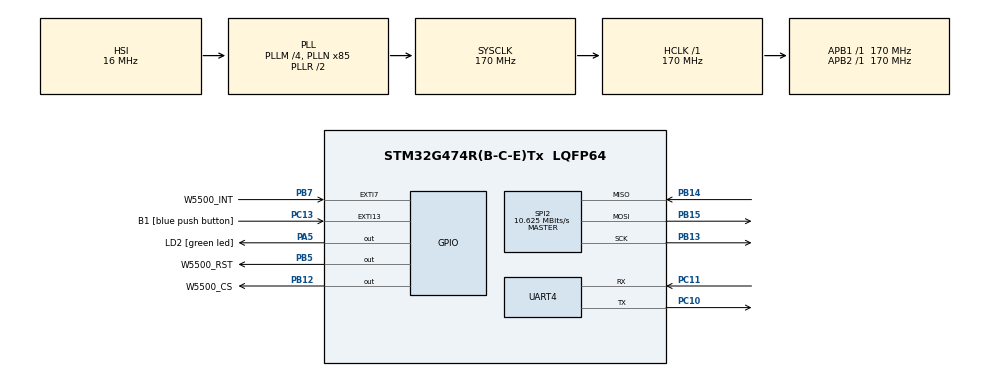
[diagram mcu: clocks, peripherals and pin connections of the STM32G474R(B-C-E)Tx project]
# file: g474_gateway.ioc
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FREERTOS.Tasks01=defaultTask,24,128,StartDefaultTask,Default,NULL,Dynamic,NULL,NULL;RS422Task,40,512,StartRS422Task,Default,NULL,Dynamic,NULL,NULL;EthernetTask,24,512,StartEthernetTask,Default,NULL,Dynamic,NULL,NULL;HealthTask,8,128,StartHealthTask,Default,NULL,Dynamic,NULL,NULL
FREERTOS.configTOTAL_HEAP_SIZE=16384
Mcu.Family=STM32G4
Mcu.Name=STM32G474R(B-C-E)Tx
Mcu.Package=LQFP64
NVIC.EXTI15_10_IRQn=true\:5\:0\:false\:false\:true\:true\:true\:true\:true
NVIC.EXTI9_5_IRQn=true\:5\:0\:false\:false\:true\:true\:true\:true\:true
NVIC.PriorityGroup=NVIC_PRIORITYGROUP_4
NVIC.TIM6_DAC_IRQn=true\:15\:0\:false\:false\:true\:false\:false\:true\:true
NVIC.TimeBase=TIM6_DAC_IRQn
NVIC.TimeBaseIP=TIM6
NVIC.UART4_IRQn=true\:5\:0\:false\:false\:true\:true\:true\:true\:true
PA13.GPIO_Label=T_SWDIO
PA13.Signal=SYS_JTMS-SWDIO
PA14.GPIO_Label=T_SWCLK
PA14.Signal=SYS_JTCK-SWCLK
PA2.GPIO_Label=LPUART1_TX [STLINKV3E_VCP_RX]
PA2.Signal=LPUART1_TX
PA3.GPIO_Label=LPUART1_RX [STLINKV3E_VCP_TX]
PA3.Signal=LPUART1_RX
PA5.GPIO_Label=LD2 [green led]
PA5.Signal=GPIO_Output
PB12.GPIO_Label=W5500_CS
PB12.GPIO_Speed=GPIO_SPEED_FREQ_HIGH
PB12.PinState=GPIO_PIN_SET
PB12.Signal=GPIO_Output
PB13.GPIO_Speed=GPIO_SPEED_FREQ_HIGH
PB13.Mode=Full_Duplex_Master
PB13.Signal=SPI2_SCK
PB14.GPIO_Speed=GPIO_SPEED_FREQ_HIGH
PB14.Mode=Full_Duplex_Master
PB14.Signal=SPI2_MISO
PB15.GPIO_Speed=GPIO_SPEED_FREQ_HIGH
PB15.Mode=Full_Duplex_Master
PB15.Signal=SPI2_MOSI
PB3.GPIO_Label=T_SWO
PB3.Signal=SYS_JTDO-SWO
PB5.GPIO_Label=W5500_RST
PB5.PinState=GPIO_PIN_SET
PB5.Signal=GPIO_Output
PB7.GPIO_Label=W5500_INT
PB7.GPIO_ModeDefaultEXTI=GPIO_MODE_IT_FALLING
PB7.Signal=GPXTI7
PC10.Mode=Asynchronous
PC10.Signal=UART4_TX
PC11.Mode=Asynchronous
PC11.Signal=UART4_RX
PC13.GPIO_Label=B1 [blue push button]
PC13.Signal=GPXTI13
PC14-OSC32_IN.GPIO_Label=RCC_OSC32_IN
PC14-OSC32_IN.Signal=RCC_OSC32_IN
PC15-OSC32_OUT.GPIO_Label=RCC_OSC32_OUT
PC15-OSC32_OUT.Signal=RCC_OSC32_OUT
PF0-OSC_IN.GPIO_Label=RCC_OSC_IN
PF0-OSC_IN.Signal=RCC_OSC_IN
PF1-OSC_OUT.GPIO_Label=RCC_OSC_OUT
PF1-OSC_OUT.Signal=RCC_OSC_OUT
ProjectManager.HeapSize=0x200
ProjectManager.StackSize=0x400
ProjectManager.TargetToolchain=STM32CubeIDE
RCC.ADC12Freq_Value=170000000
RCC.ADC345Freq_Value=170000000
RCC.AHBFreq_Value=170000000
RCC.APB1Freq_Value=170000000
RCC.APB1TimFreq_Value=170000000
RCC.APB2Freq_Value=170000000
RCC.APB2TimFreq_Value=170000000
RCC.CortexFreq_Value=170000000
RCC.EXTERNAL_CLOCK_VALUE=12288000
RCC.HCLKFreq_Value=170000000
RCC.HSE_VALUE=24000000
RCC.HSI48_VALUE=48000000
RCC.HSI_VALUE=16000000
RCC.LSE_VALUE=32768
RCC.PLLM=RCC_PLLM_DIV4
RCC.PLLN=85
RCC.RTCClockSelection=RCC_RTCCLKSOURCE_LSE
RCC.SYSCLKFreq_VALUE=170000000
RCC.SYSCLKSource=RCC_SYSCLKSOURCE_PLLCLK
RCC.USBFreq_Value=170000000
RCC.VCOOutputFreq_Value=340000000
SPI2.BaudRatePrescaler=SPI_BAUDRATEPRESCALER_16
SPI2.CalculateBaudRate=10.625 MBits/s
SPI2.DataSize=SPI_DATASIZE_8BIT
SPI2.Direction=SPI_DIRECTION_2LINES
SPI2.Mode=SPI_MODE_MASTER
SPI2.VirtualType=VM_MASTER
VP_FREERTOS_VS_CMSIS_V2.Mode=CMSIS_V2
VP_SYS_VS_DBSignals.Mode=DisableDeadBatterySignals
VP_SYS_VS_tim6.Mode=TIM6
board=NUCLEO-G474RE

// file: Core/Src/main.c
/* USER CODE BEGIN Header */
/**
  ******************************************************************************
  * @file           : main.c
  * @brief          : Main program body
  ******************************************************************************
  * @attention
  *
  * Copyright (c) 2026 STMicroelectronics.
  * All rights reserved.
  *
  * This software is licensed under terms that can be found in the LICENSE file
  * in the root directory of this software component.
  * If no LICENSE file comes with this software, it is provided AS-IS.
  *
  ******************************************************************************
  */
/* USER CODE END Header */
#include "main.h"
#include "cmsis_os.h"

/* USER CODE BEGIN Includes */
#include "FreeRTOS.h"
#include "protocol.h"
#include "stream_parser.h"

/* USER CODE END Includes */

/* USER CODE BEGIN PTD */
typedef enum
{
  RS422_PING_TEST_NOT_RUN = 0,
  RS422_PING_TEST_PASS = 1,
  RS422_PING_TEST_ENCODE_FAILURE = -1,
  RS422_PING_TEST_TX_FAILURE = -2,
  RS422_PING_TEST_PONG_TIMEOUT = -3,
  RS422_PING_TEST_RX_FAILURE = -4
} rs422_ping_test_result_t;

typedef enum
{
  COMM_INIT = 0,
  COMM_OK,
  COMM_TIMEOUT
} rs422_comm_state_t;

/* USER CODE END PTD */

/* USER CODE BEGIN PD */
#define RS422_BRINGUP_TEST_COUNT          100u
#define RS422_BRINGUP_TX_TIMEOUT_MS       100u
#define RS422_BRINGUP_PONG_TIMEOUT_MS     1000u
#define RS422_BRINGUP_INTER_TEST_DELAY_MS 20u
#define RS422_EVENT_RX                     (1UL << 0)
#define RS422_EVENT_TX_DONE                (1UL << 1)
#define RS422_EVENT_CMD_READY              (1UL << 2)
#define RS422_EVENT_TCP_CONTEXT_RESET      (1UL << 3)
#define RS422_EVENT_MASK                   (RS422_EVENT_RX | RS422_EVENT_TX_DONE | \
                                            RS422_EVENT_CMD_READY | \
                                            RS422_EVENT_TCP_CONTEXT_RESET)
#define RS422_RX_RING_CAPACITY             512u
#define RS422_RX_RING_MASK                 (RS422_RX_RING_CAPACITY - 1u)
#define RS422_CMD_QUEUE_DEPTH              8u
#define TCP_RESPONSE_QUEUE_DEPTH           8u
#define UDP_TELEMETRY_QUEUE_DEPTH          4u
#define HEALTH_TASK_PERIOD_MS              100u
#define RS422_COMM_TIMEOUT_MS              1500u
#define W5500_RESET_DELAY_MS               2u
#define W5500_SPI_TIMEOUT_MS               100u
#define W5500_VERSIONR_ADDRESS             0x0039u
#define W5500_PHYCFGR_ADDRESS              0x002eu
#define W5500_PHYCFGR_LNK                  0x01u
#define W5500_PHY_POLL_PERIOD_MS           100u
#define W5500_DATA_SERVICE_PERIOD_MS        1u
#define ETHERNET_EVENT_TCP_RESPONSE_READY  (1UL << 0)
#define ETHERNET_EVENT_MASK                ETHERNET_EVENT_TCP_RESPONSE_READY
#define DIAG_TIMESTAMP_NOT_CAPTURED_MS      UINT32_MAX
#define W5500_GAR_ADDRESS                  0x0001u
#define W5500_SUBR_ADDRESS                 0x0005u
#define W5500_SHAR_ADDRESS                 0x0009u
#define W5500_SIPR_ADDRESS                 0x000fu
#define W5500_GAR_LENGTH                   4u
#define W5500_SUBR_LENGTH                  4u
#define W5500_SHAR_LENGTH                  6u
#define W5500_SIPR_LENGTH                  4u
#define W5500_NET_MAX_REGISTER_LENGTH      W5500_SHAR_LENGTH
#define W5500_COMMON_HEADER_LENGTH         3u
/* BSB[4:0] = 00000 (Common), RWB = 0 (Read), OM[1:0] = 00 (VDM). */
#define W5500_COMMON_READ_VDM              0x00u
/* BSB[4:0] = 00000 (Common), RWB = 1 (Write), OM[1:0] = 00 (VDM). */
#define W5500_COMMON_WRITE_VDM             0x04u
#define W5500_SOCKET0_READ_VDM             0x08u
#define W5500_SOCKET0_WRITE_VDM            0x0cu
#define W5500_SOCKET0_MR_ADDRESS           0x0000u
#define W5500_SOCKET0_CR_ADDRESS           0x0001u
#define W5500_SOCKET0_IR_ADDRESS           0x0002u
#define W5500_SOCKET0_SR_ADDRESS           0x0003u
#define W5500_SOCKET0_PORT_ADDRESS         0x0004u
#define W5500_SOCKET0_TX_FSR_ADDRESS       0x0020u
#define W5500_SOCKET0_TX_WR_ADDRESS        0x0024u
#define W5500_SOCKET0_RX_RSR_ADDRESS       0x0026u
#define W5500_SOCKET0_RX_RD_ADDRESS        0x0028u
#define W5500_SOCKET0_MAX_DATA_LENGTH      2u
#define W5500_SOCKET0_TX_BUFFER_WRITE_VDM  0x14u
#define W5500_SOCKET0_RX_BUFFER_READ_VDM   0x18u
#define W5500_SOCKET0_TCP_MODE             0x01u
#define W5500_SOCKET0_OPEN_COMMAND         0x01u
#define W5500_SOCKET0_LISTEN_COMMAND       0x02u
#define W5500_SOCKET0_DISCON_COMMAND       0x08u
#define W5500_SOCKET0_CLOSE_COMMAND        0x10u
#define W5500_SOCKET0_SEND_COMMAND         0x20u
#define W5500_SOCKET0_RECV_COMMAND         0x40u
#define W5500_SOCKET0_IR_SEND_OK           0x10u
#define W5500_SOCKET0_IR_TIMEOUT           0x08u
#define W5500_SOCKET0_STATUS_CLOSED        0x00u
#define W5500_SOCKET0_STATUS_INIT          0x13u
#define W5500_SOCKET0_STATUS_LISTEN        0x14u
#define W5500_SOCKET0_STATUS_SYNSENT       0x15u
#define W5500_SOCKET0_STATUS_SYNRECV       0x16u
#define W5500_SOCKET0_STATUS_ESTABLISHED   0x17u
#define W5500_SOCKET0_STATUS_FIN_WAIT      0x18u
#define W5500_SOCKET0_STATUS_CLOSING       0x1au
#define W5500_SOCKET0_STATUS_TIME_WAIT     0x1bu
#define W5500_SOCKET0_STATUS_CLOSE_WAIT    0x1cu
#define W5500_SOCKET0_STATUS_LAST_ACK      0x1du
#define W5500_TCP_SERVER_PORT              5000u
#define W5500_SOCKET_STATE_TIMEOUT_MS      1000u
#define W5500_SOCKET_STATE_POLL_MS         10u
#define W5500_TCP_TRANSIENT_TIMEOUT_MS     3000u
#define W5500_TCP_RECOVERY_RETRY_MS        500u
#define W5500_TCP_STABLE_READ_ATTEMPTS     8u
#define W5500_TCP_RX_CHUNK_SIZE            64u
#define W5500_TCP_TX_FREE_TIMEOUT_MS       1000u
#define W5500_TCP_SEND_TIMEOUT_MS          1000u
#define W5500_TCP_IO_POLL_MS               10u
#define W5500_SOCKET_COMMAND_TIMEOUT_MS    100u
#define W5500_SOCKET_COMMAND_POLL_MS       1u
#define W5500_SOCKET1_READ_VDM             0x28u
#define W5500_SOCKET1_WRITE_VDM            0x2cu
#define W5500_SOCKET1_TX_BUFFER_WRITE_VDM  0x34u
#define W5500_SOCKET1_MR_ADDRESS           0x0000u
#define W5500_SOCKET1_CR_ADDRESS           0x0001u
#define W5500_SOCKET1_IR_ADDRESS           0x0002u
#define W5500_SOCKET1_SR_ADDRESS           0x0003u
#define W5500_SOCKET1_PORT_ADDRESS         0x0004u
#define W5500_SOCKET1_DIPR_ADDRESS         0x000cu
#define W5500_SOCKET1_DPORT_ADDRESS        0x0010u
#define W5500_SOCKET1_TX_FSR_ADDRESS       0x0020u
#define W5500_SOCKET1_TX_WR_ADDRESS        0x0024u
#define W5500_SOCKET1_MAX_DATA_LENGTH      4u
#define W5500_SOCKET1_UDP_MODE             0x02u
#define W5500_SOCKET1_OPEN_COMMAND         0x01u
#define W5500_SOCKET1_SEND_COMMAND         0x20u
#define W5500_SOCKET1_IR_SEND_OK           0x10u
#define W5500_SOCKET1_IR_TIMEOUT           0x08u
#define W5500_SOCKET1_STATUS_CLOSED        0x00u
#define W5500_SOCKET1_STATUS_UDP           0x22u
#define W5500_UDP_LOCAL_PORT               5001u
#define W5500_UDP_DESTINATION_PORT         5002u
#define W5500_UDP_PAYLOAD_LENGTH           6u
#define W5500_UDP_STABLE_READ_ATTEMPTS     8u
#define W5500_UDP_TX_FREE_TIMEOUT_MS       1000u
#define W5500_UDP_SEND_TIMEOUT_MS          1000u
#define W5500_UDP_IO_POLL_MS               10u
#define W5500_UDP_SPI_CHUNK_SIZE           64u
/* Day 8 forwards only F429 telemetry; retain the Day 6 generator disabled. */
#define W5500_UDP_LOCAL_TELEMETRY_ENABLED  0u
/* F429 produces every 100 ms; two sends clear one-cycle scheduling backlog. */
#define UDP_TELEMETRY_DRAIN_LIMIT          2u

/* USER CODE END PD */

SPI_HandleTypeDef hspi2;

UART_HandleTypeDef huart4;

/* Definitions for defaultTask */
osThreadId_t defaultTaskHandle;
const osThreadAttr_t defaultTask_attributes = {
  .name = "defaultTask",
  .priority = (osPriority_t) osPriorityNormal,
  .stack_size = 128 * 4
};
/* Definitions for RS422Task */
osThreadId_t RS422TaskHandle;
const osThreadAttr_t RS422Task_attributes = {
  .name = "RS422Task",
  .priority = (osPriority_t) osPriorityHigh,
  .stack_size = 512 * 4
};
/* Definitions for EthernetTask */
osThreadId_t EthernetTaskHandle;
const osThreadAttr_t EthernetTask_attributes = {
  .name = "EthernetTask",
  .priority = (osPriority_t) osPriorityNormal,
  .stack_size = 512 * 4
};
/* Definitions for HealthTask */
osThreadId_t HealthTaskHandle;
const osThreadAttr_t HealthTask_attributes = {
  .name = "HealthTask",
  .priority = (osPriority_t) osPriorityLow,
  .stack_size = 128 * 4
};
/* USER CODE BEGIN PV */
static volatile int32_t g_rs422_ping_test_result = RS422_PING_TEST_NOT_RUN;
static volatile uint8_t g_rs422_last_msg_id = 0u;
static volatile uint16_t g_rs422_last_seq = 0u;
static volatile uint32_t g_rs422_rx_frame_count = 0u;
static volatile uint32_t g_rs422_test_total = 0u;
static volatile uint32_t g_rs422_test_success = 0u;
static volatile uint32_t g_rs422_test_fail = 0u;
static volatile uint32_t g_rs422_rx_overflow_count = 0u;
static volatile uint32_t g_rs422_uart_rx_error_count = 0u;
static volatile uint32_t g_rs422_tx_busy = 0u;
static volatile uint32_t g_rs422_tx_complete_count = 0u;
static volatile uint32_t g_rs422_tx_busy_count = 0u;
static volatile uint32_t g_rs422_tx_error_count = 0u;
static volatile uint32_t g_rs422_tx_timeout_count = 0u;
static volatile uint32_t g_rs422_cmd_enqueue_success_count = 0u;
static volatile uint32_t g_rs422_cmd_enqueue_fail_count = 0u;
static volatile uint32_t g_rs422_cmd_dequeue_count = 0u;
static volatile uint32_t g_rs422_forwarded_pong_rx_count = 0u;
static volatile uint32_t g_tcp_response_enqueue_success_count = 0u;
static volatile uint32_t g_tcp_response_enqueue_fail_count = 0u;
static volatile uint32_t g_tcp_response_dequeue_count = 0u;
static volatile uint32_t g_rs422_telemetry_rx_count = 0u;
static volatile uint32_t g_udp_telemetry_enqueue_success_count = 0u;
static volatile uint32_t g_udp_telemetry_enqueue_fail_count = 0u;
static volatile uint32_t g_udp_telemetry_dequeue_count = 0u;
static volatile uint32_t g_rs422_telemetry_forwarding_enabled = 0u;
static volatile uint32_t g_rs422_tcp_ping_pending = 0u;
static volatile uint16_t g_rs422_tcp_ping_pending_seq = 0u;
static volatile uint8_t g_rs422_last_tx_msg_id = 0u;
static volatile uint16_t g_rs422_last_tx_seq = 0u;
static volatile uint32_t g_rs422_last_valid_frame_tick = 0u;
static volatile uint32_t g_rs422_has_valid_frame = 0u;
static volatile rs422_comm_state_t g_rs422_comm_state = COMM_INIT;
static volatile uint32_t g_rs422_comm_timeout_count = 0u;
static volatile uint32_t g_rs422_comm_recovery_count = 0u;
static volatile uint32_t g_rs422_diag_last_valid_frame_ms =
  DIAG_TIMESTAMP_NOT_CAPTURED_MS;
static volatile uint32_t g_rs422_diag_timeout_transition_ms =
  DIAG_TIMESTAMP_NOT_CAPTURED_MS;
static volatile uint32_t g_rs422_diag_recovery_first_valid_ms =
  DIAG_TIMESTAMP_NOT_CAPTURED_MS;
static volatile uint32_t g_rs422_diag_recovery_comm_ok_ms =
  DIAG_TIMESTAMP_NOT_CAPTURED_MS;
static volatile uint32_t g_rs422_diag_fault_detection_ms =
  DIAG_TIMESTAMP_NOT_CAPTURED_MS;
static volatile uint32_t g_rs422_diag_recovery_ms =
  DIAG_TIMESTAMP_NOT_CAPTURED_MS;
static volatile uint32_t g_rs422_diag_timeout_transition_tick = UINT32_MAX;
static volatile uint32_t g_rs422_diag_recovery_first_valid_tick = UINT32_MAX;
static volatile uint32_t g_rs422_diag_recovery_comm_ok_tick = UINT32_MAX;
static volatile uint32_t g_gateway_queue_init_ok = 0u;
static volatile uint32_t g_gateway_free_heap_bytes = 0u;
static volatile uint32_t g_gateway_min_ever_free_heap_bytes = 0u;
static volatile uint8_t g_w5500_version = 0u;
/* -1: not completed; otherwise HAL_OK/ERROR/BUSY/TIMEOUT = 0/1/2/3. */
static volatile int32_t g_w5500_spi_status = -1;
/* Retain the last successful PHY sample on error; always check PHY SPI status. */
static volatile uint8_t g_w5500_phycfgr = 0u;
static volatile uint32_t g_w5500_link_up = 0u;
static volatile uint32_t g_w5500_link_down_count = 0u;
static volatile uint32_t g_w5500_link_recovery_count = 0u;
static volatile int32_t g_w5500_phy_spi_status = -1;
static volatile uint32_t g_w5500_net_config_ok = 0u;
static volatile uint32_t g_w5500_net_readback_ok = 0u;
static volatile int32_t g_w5500_net_write_status = -1;
static volatile int32_t g_w5500_net_read_status = -1;
static uint8_t g_w5500_gar_readback[W5500_GAR_LENGTH] = {0u};
static uint8_t g_w5500_subr_readback[W5500_SUBR_LENGTH] = {0u};
static uint8_t g_w5500_shar_readback[W5500_SHAR_LENGTH] = {0u};
static uint8_t g_w5500_sipr_readback[W5500_SIPR_LENGTH] = {0u};
static const uint8_t g_w5500_net_gateway[W5500_GAR_LENGTH] = {
  0u, 0u, 0u, 0u
};
static const uint8_t g_w5500_net_subnet[W5500_SUBR_LENGTH] = {
  255u, 255u, 255u, 0u
};
static const uint8_t g_w5500_net_mac[W5500_SHAR_LENGTH] = {
  0x02u, 0x00u, 0x00u, 0x00u, 0x00u, 0x02u
};
static const uint8_t g_w5500_net_ip[W5500_SIPR_LENGTH] = {
  192u, 168u, 77u, 2u
};
static volatile uint32_t g_w5500_tcp_init_ok = 0u;
static volatile uint32_t g_w5500_tcp_listen_ok = 0u;
static volatile uint8_t g_w5500_socket0_status = W5500_SOCKET0_STATUS_CLOSED;
static volatile int32_t g_w5500_socket0_spi_status = -1;
static volatile uint32_t g_w5500_tcp_rx_bytes = 0u;
static volatile uint32_t g_w5500_tcp_tx_bytes = 0u;
static volatile uint32_t g_w5500_tcp_valid_frame_count = 0u;
static volatile uint32_t g_w5500_tcp_ping_count = 0u;
static volatile uint32_t g_w5500_tcp_pong_count = 0u;
static volatile uint8_t g_w5500_tcp_last_rx_msg_id = 0u;
static volatile uint16_t g_w5500_tcp_last_rx_seq = 0u;
static volatile uint8_t g_w5500_tcp_last_tx_msg_id = 0u;
static volatile uint16_t g_w5500_tcp_last_tx_seq = 0u;
static volatile uint32_t g_w5500_tcp_rx_error_count = 0u;
static volatile uint32_t g_w5500_tcp_tx_error_count = 0u;
static volatile int32_t g_w5500_tcp_last_rx_status = -1;
static volatile int32_t g_w5500_tcp_last_tx_status = -1;
static volatile uint32_t g_w5500_tcp_recovery_pending = 0u;
static volatile uint32_t g_w5500_tcp_recovery_attempt_count = 0u;
static volatile uint32_t g_w5500_tcp_recovery_success_count = 0u;
static volatile uint32_t g_w5500_tcp_recovery_fail_count = 0u;
static volatile uint32_t g_eth_diag_link_down_observed_ms =
  DIAG_TIMESTAMP_NOT_CAPTURED_MS;
static volatile uint32_t g_eth_diag_link_up_observed_ms =
  DIAG_TIMESTAMP_NOT_CAPTURED_MS;
static volatile uint32_t g_eth_diag_tcp_service_ready_ms =
  DIAG_TIMESTAMP_NOT_CAPTURED_MS;
static volatile uint32_t g_eth_diag_first_tcp_pong_tx_success_ms =
  DIAG_TIMESTAMP_NOT_CAPTURED_MS;
static volatile uint32_t g_eth_diag_first_udp_tx_success_ms =
  DIAG_TIMESTAMP_NOT_CAPTURED_MS;
static volatile uint32_t g_eth_diag_linkup_to_tcp_service_ready_ms =
  DIAG_TIMESTAMP_NOT_CAPTURED_MS;
static volatile uint32_t g_eth_diag_linkup_to_tcp_pong_tx_ms =
  DIAG_TIMESTAMP_NOT_CAPTURED_MS;
static volatile uint32_t g_eth_diag_linkup_to_udp_tx_ms =
  DIAG_TIMESTAMP_NOT_CAPTURED_MS;
static volatile uint32_t g_eth_diag_recovery_cycle_active = 0u;
static volatile uint32_t g_eth_diag_link_down_tick = UINT32_MAX;
static volatile uint32_t g_eth_diag_link_up_tick = UINT32_MAX;
static volatile uint32_t g_eth_diag_tcp_service_ready_tick = UINT32_MAX;
static volatile uint32_t g_eth_diag_first_tcp_pong_tx_success_tick =
  UINT32_MAX;
static volatile uint32_t g_eth_diag_first_udp_tx_success_tick = UINT32_MAX;
static volatile uint32_t g_w5500_tcp_session_active = 0u;
static volatile uint32_t g_w5500_tcp_stale_response_drop_count = 0u;
static volatile uint32_t g_w5500_data_service_cycle_count = 0u;
static volatile uint32_t g_w5500_data_deadline_miss_count = 0u;
static volatile uint32_t g_w5500_data_overrun_count = 0u;
static volatile uint32_t g_w5500_data_max_start_late_ticks = 0u;
static volatile uint32_t g_w5500_data_max_exec_cycles = 0u;
static volatile uint32_t g_w5500_data_max_exec_us = 0u;
static volatile uint32_t g_w5500_data_cycle_counter_available = 0u;
static volatile uint32_t g_w5500_data_system_core_clock_hz = 0u;
static volatile uint32_t g_w5500_data_kernel_tick_hz = 0u;
static volatile uint32_t g_w5500_data_period_cycles = 0u;
static volatile uint32_t g_w5500_data_timing_reference_valid = 0u;
static volatile uint32_t g_diag_tcp_established_ms =
  DIAG_TIMESTAMP_NOT_CAPTURED_MS;
static volatile uint32_t g_diag_first_rx_ready_ms =
  DIAG_TIMESTAMP_NOT_CAPTURED_MS;
static volatile uint32_t g_diag_first_ping_parsed_ms =
  DIAG_TIMESTAMP_NOT_CAPTURED_MS;
static volatile uint32_t g_diag_rs422_ping_tx_ms =
  DIAG_TIMESTAMP_NOT_CAPTURED_MS;
static volatile uint32_t g_diag_matching_pong_rx_ms =
  DIAG_TIMESTAMP_NOT_CAPTURED_MS;
static volatile uint32_t g_diag_tcp_pong_send_ms =
  DIAG_TIMESTAMP_NOT_CAPTURED_MS;
static volatile uint32_t g_diag_established_to_rx_ready_ms =
  DIAG_TIMESTAMP_NOT_CAPTURED_MS;
static volatile uint32_t g_diag_rx_ready_to_ping_parsed_ms =
  DIAG_TIMESTAMP_NOT_CAPTURED_MS;
static volatile uint32_t g_diag_ping_parsed_to_rs422_tx_ms =
  DIAG_TIMESTAMP_NOT_CAPTURED_MS;
static volatile uint32_t g_diag_rs422_tx_to_matching_pong_rx_ms =
  DIAG_TIMESTAMP_NOT_CAPTURED_MS;
static volatile uint32_t g_diag_matching_pong_rx_to_tcp_send_ms =
  DIAG_TIMESTAMP_NOT_CAPTURED_MS;
static volatile uint32_t g_diag_established_to_tcp_pong_send_ms =
  DIAG_TIMESTAMP_NOT_CAPTURED_MS;
static volatile uint16_t g_diag_first_ping_seq = 0u;
static volatile uint32_t g_diag_first_ping_seq_valid = 0u;
static volatile uint32_t g_w5500_udp_open_ok = 0u;
static volatile uint8_t g_w5500_udp_socket1_status = W5500_SOCKET1_STATUS_CLOSED;
static volatile int32_t g_w5500_udp_socket1_spi_status = -1;
static volatile uint32_t g_w5500_udp_tx_packet_count = 0u;
static volatile uint32_t g_w5500_udp_tx_bytes = 0u;
static volatile uint32_t g_w5500_udp_tx_error_count = 0u;
static volatile uint16_t g_w5500_udp_last_tx_seq = 0u;
static volatile int32_t g_w5500_udp_last_tx_status = -1;
static volatile uint16_t g_w5500_udp_next_seq = 1u;
static osMessageQueueId_t rs422_cmd_queue = NULL;
static osMessageQueueId_t tcp_response_queue = NULL;
static osMessageQueueId_t udp_telemetry_queue = NULL;
static const osMessageQueueAttr_t rs422_cmd_queue_attributes = {
  .name = "rs422_cmd_queue"
};
static const osMessageQueueAttr_t tcp_response_queue_attributes = {
  .name = "tcp_response_queue"
};
static const osMessageQueueAttr_t udp_telemetry_queue_attributes = {
  .name = "udp_telemetry_queue"
};
static protocol_packet_t g_rs422_ping_packet;
static protocol_packet_t g_rs422_command_packet;
static protocol_packet_t g_rs422_received_packet;
static stream_parser_t g_rs422_parser;
static uint8_t g_rs422_tx_frame[PROTOCOL_MAX_FRAME_SIZE];
static uint8_t g_uart4_rx_byte;
static uint8_t g_rs422_rx_ring[RS422_RX_RING_CAPACITY];
static volatile uint16_t g_rs422_rx_head = 0u;
static volatile uint16_t g_rs422_rx_tail = 0u;
static stream_parser_t g_tcp_parser;
static protocol_packet_t g_tcp_received_packet;
static protocol_packet_t g_tcp_pong_packet;
static uint8_t g_w5500_tcp_rx_chunk[W5500_TCP_RX_CHUNK_SIZE];
static uint8_t g_w5500_tcp_rx_dummy[W5500_TCP_RX_CHUNK_SIZE];
static uint8_t g_w5500_tcp_tx_frame[PROTOCOL_MAX_FRAME_SIZE];
static const uint8_t g_w5500_udp_destination_ip[4] = {
  192u, 168u, 77u, 1u
};
static protocol_packet_t g_udp_telemetry_packet;
static protocol_packet_t g_udp_forward_packet;
static uint8_t g_w5500_udp_tx_frame[PROTOCOL_MAX_FRAME_SIZE];
static uint8_t g_w5500_udp_spi_discard[W5500_UDP_SPI_CHUNK_SIZE];

/* USER CODE END PV */

void SystemClock_Config(void);
static void MX_GPIO_Init(void);
static void MX_SPI2_Init(void);
static void MX_UART4_Init(void);
void StartDefaultTask(void *argument);
void StartRS422Task(void *argument);
void StartEthernetTask(void *argument);
void StartHealthTask(void *argument);

/* USER CODE BEGIN PFP */
static void rs422_rx_ring_push_from_isr(uint8_t byte);
static uint32_t rs422_rx_ring_pop(uint8_t *byte);
static uint32_t rs422_ms_to_kernel_ticks(uint32_t time_ms);
static uint32_t rs422_kernel_ticks_to_ms(uint32_t ticks);
static void rs422_diag_record_timeout_transition(
  uint32_t timeout_tick,
  uint32_t has_valid_frame,
  uint32_t last_valid_frame_tick);
static void ethernet_diag_initialize(void);
static void ethernet_diag_arm_recovery(uint32_t link_down_tick);
static void ethernet_diag_record_link_up(uint32_t link_up_tick);
static void ethernet_diag_record_tcp_service_ready(void);
static void ethernet_diag_record_tcp_pong_tx_success(void);
static void ethernet_diag_record_udp_tx_success(void);
static uint32_t diagnostic_now_ms(void);
static void diagnostic_begin_tcp_session(uint32_t established_ms);
static uint32_t rs422_process_rx_buffer(
  uint16_t expected_pong_sequence,
  uint32_t match_pong);
static void rs422_handle_tcp_context_reset_event(uint32_t flags);
static void rs422_handle_tx_done_event(uint32_t flags);
static int32_t rs422_wait_for_tx_complete(
  uint16_t expected_pong_sequence,
  uint32_t *matching_pong_received);
static int32_t rs422_ping_bringup_test(uint16_t sequence);
static int32_t rs422_ping_bringup_run(void);
static int32_t rs422_forward_packet(const protocol_packet_t *packet);
static void w5500_hardware_reset(void);
static HAL_StatusTypeDef w5500_read_version(uint8_t *version);
static HAL_StatusTypeDef w5500_read_common_register(uint16_t address, uint8_t *value);
static HAL_StatusTypeDef w5500_write_common_registers(
  uint16_t address,
  const uint8_t *data,
  uint16_t length);
static HAL_StatusTypeDef w5500_read_common_registers(
  uint16_t address,
  uint8_t *data,
  uint16_t length);
static HAL_StatusTypeDef w5500_write_network_config(void);
static HAL_StatusTypeDef w5500_read_network_config(void);
static uint32_t w5500_network_readback_matches(void);
static HAL_StatusTypeDef w5500_socket0_write_registers(
  uint16_t address,
  const uint8_t *data,
  uint16_t length);
static HAL_StatusTypeDef w5500_socket0_read_register(
  uint16_t address,
  uint8_t *value);
static HAL_StatusTypeDef w5500_socket0_execute_command(uint8_t command);
static HAL_StatusTypeDef w5500_socket0_read_registers(
  uint16_t address,
  uint8_t *data,
  uint16_t length);
static HAL_StatusTypeDef w5500_socket0_read_u16(
  uint16_t address,
  uint16_t *value);
static HAL_StatusTypeDef w5500_socket0_read_stable_u16(
  uint16_t address,
  uint16_t *value);
static HAL_StatusTypeDef w5500_socket0_write_tx_buffer(
  uint16_t address,
  const uint8_t *data,
  uint16_t length);
static HAL_StatusTypeDef w5500_socket0_read_rx_buffer(
  uint16_t address,
  uint8_t *data,
  uint16_t length);
static HAL_StatusTypeDef w5500_tcp_wait_for_tx_free(
  uint16_t required_size);
static HAL_StatusTypeDef w5500_tcp_wait_for_send_result(void);
static HAL_StatusTypeDef w5500_tcp_send_frame(
  const uint8_t *frame,
  uint16_t frame_length);
static void w5500_tcp_send_response_packet(const protocol_packet_t *packet);
static void w5500_tcp_handle_valid_frame(void);
static HAL_StatusTypeDef w5500_tcp_process_rx(void);
static HAL_StatusTypeDef w5500_wait_for_socket0_status(
  uint8_t expected_status,
  uint32_t timeout_ms);
static HAL_StatusTypeDef w5500_listen_tcp_server(void);
static HAL_StatusTypeDef w5500_start_tcp_server(void);
static HAL_StatusTypeDef w5500_restart_tcp_server(void);
static uint32_t w5500_tcp_is_transient_state(uint8_t socket_status);
static void w5500_tcp_invalidate_connection_context(void);
static void w5500_tcp_discard_stale_responses(void);
static void w5500_tcp_drain_response_queue(void);
static HAL_StatusTypeDef w5500_socket1_write_registers(
  uint16_t address,
  const uint8_t *data,
  uint16_t length);
static HAL_StatusTypeDef w5500_socket1_read_register(
  uint16_t address,
  uint8_t *value);
static HAL_StatusTypeDef w5500_socket1_read_registers(
  uint16_t address,
  uint8_t *data,
  uint16_t length);
static HAL_StatusTypeDef w5500_socket1_read_u16(
  uint16_t address,
  uint16_t *value);
static HAL_StatusTypeDef w5500_socket1_read_stable_u16(
  uint16_t address,
  uint16_t *value);
static HAL_StatusTypeDef w5500_socket1_write_tx_buffer(
  uint16_t address,
  const uint8_t *data,
  uint16_t length);
static HAL_StatusTypeDef w5500_socket1_execute_command(uint8_t command);
static HAL_StatusTypeDef w5500_wait_for_socket1_status(
  uint8_t expected_status,
  uint32_t timeout_ms);
static HAL_StatusTypeDef w5500_udp_wait_for_tx_free(
  uint16_t required_size);
static HAL_StatusTypeDef w5500_udp_wait_for_send_result(void);
static HAL_StatusTypeDef w5500_udp_send_frame(
  const uint8_t *frame,
  uint16_t frame_length);
static HAL_StatusTypeDef w5500_start_udp_socket(void);
static uint32_t w5500_kernel_uptime_ms(void);
static void w5500_udp_send_telemetry(void);
static HAL_StatusTypeDef w5500_udp_forward_packet(
  const protocol_packet_t *packet);

/* USER CODE END PFP */

/* USER CODE BEGIN 0 */
static void w5500_hardware_reset(void)
{
  /* Add one tick so tick phase cannot shorten either delay below 2 ms.
     Reset low must be >= 500 us; PLL lock takes at most 1 ms after release. */
  const uint32_t delay_ticks = (uint32_t)(
    (((uint64_t)W5500_RESET_DELAY_MS * osKernelGetTickFreq()) + 999u) / 1000u) + 1u;

  HAL_GPIO_WritePin(W5500_CS_GPIO_Port, W5500_CS_Pin, GPIO_PIN_SET);
  HAL_GPIO_WritePin(W5500_RST_GPIO_Port, W5500_RST_Pin, GPIO_PIN_RESET);
  (void)osDelay(delay_ticks);
  HAL_GPIO_WritePin(W5500_RST_GPIO_Port, W5500_RST_Pin, GPIO_PIN_SET);
  (void)osDelay(delay_ticks);
}

static HAL_StatusTypeDef w5500_read_version(uint8_t *version)
{
  return w5500_read_common_register(W5500_VERSIONR_ADDRESS, version);
}

static HAL_StatusTypeDef w5500_read_common_register(uint16_t address, uint8_t *value)
{
  const uint8_t tx[4] = {
    (uint8_t)(address >> 8),
    (uint8_t)(address & 0xffu),
    W5500_COMMON_READ_VDM,
    0u /* Dummy byte clocks the register data out on MISO. */
  };
  uint8_t rx[4] = {0u};

  /* Keep CS low for address, control and data in one full-duplex transfer. */
  HAL_GPIO_WritePin(W5500_CS_GPIO_Port, W5500_CS_Pin, GPIO_PIN_RESET);
  const HAL_StatusTypeDef status = HAL_SPI_TransmitReceive(
    &hspi2, tx, rx, (uint16_t)sizeof(tx), W5500_SPI_TIMEOUT_MS);
  HAL_GPIO_WritePin(W5500_CS_GPIO_Port, W5500_CS_Pin, GPIO_PIN_SET);

  if (status == HAL_OK)
  {
    *value = rx[3];
  }

  return status;
}

static HAL_StatusTypeDef w5500_write_common_registers(
  uint16_t address,
  const uint8_t *data,
  uint16_t length)
{
  uint8_t tx[W5500_COMMON_HEADER_LENGTH + W5500_NET_MAX_REGISTER_LENGTH];

  /* length is the Data Phase byte count; it excludes address and control. */
  if ((data == NULL) || (length == 0u) ||
      (length > W5500_NET_MAX_REGISTER_LENGTH))
  {
    return HAL_ERROR;
  }

  tx[0] = (uint8_t)(address >> 8);
  tx[1] = (uint8_t)(address & 0xffu);
  tx[2] = W5500_COMMON_WRITE_VDM;
  for (uint16_t index = 0u; index < length; index++)
  {
    tx[W5500_COMMON_HEADER_LENGTH + index] = data[index];
  }

  HAL_GPIO_WritePin(W5500_CS_GPIO_Port, W5500_CS_Pin, GPIO_PIN_RESET);
  const HAL_StatusTypeDef status = HAL_SPI_Transmit(
    &hspi2,
    tx,
    (uint16_t)(W5500_COMMON_HEADER_LENGTH + length),
    W5500_SPI_TIMEOUT_MS);
  HAL_GPIO_WritePin(W5500_CS_GPIO_Port, W5500_CS_Pin, GPIO_PIN_SET);

  return status;
}

static HAL_StatusTypeDef w5500_read_common_registers(
  uint16_t address,
  uint8_t *data,
  uint16_t length)
{
  uint8_t tx[W5500_COMMON_HEADER_LENGTH + W5500_NET_MAX_REGISTER_LENGTH] = {0u};
  uint8_t rx[W5500_COMMON_HEADER_LENGTH + W5500_NET_MAX_REGISTER_LENGTH] = {0u};

  /* length is the Data Phase byte count; it excludes address and control. */
  if ((data == NULL) || (length == 0u) ||
      (length > W5500_NET_MAX_REGISTER_LENGTH))
  {
    return HAL_ERROR;
  }

  tx[0] = (uint8_t)(address >> 8);
  tx[1] = (uint8_t)(address & 0xffu);
  tx[2] = W5500_COMMON_READ_VDM;

  HAL_GPIO_WritePin(W5500_CS_GPIO_Port, W5500_CS_Pin, GPIO_PIN_RESET);
  const HAL_StatusTypeDef status = HAL_SPI_TransmitReceive(
    &hspi2,
    tx,
    rx,
    (uint16_t)(W5500_COMMON_HEADER_LENGTH + length),
    W5500_SPI_TIMEOUT_MS);
  HAL_GPIO_WritePin(W5500_CS_GPIO_Port, W5500_CS_Pin, GPIO_PIN_SET);

  if (status == HAL_OK)
  {
    for (uint16_t index = 0u; index < length; index++)
    {
      data[index] = rx[W5500_COMMON_HEADER_LENGTH + index];
    }
  }

  return status;
}

static HAL_StatusTypeDef w5500_write_network_config(void)
{
  HAL_StatusTypeDef status = w5500_write_common_registers(
    W5500_GAR_ADDRESS, g_w5500_net_gateway, W5500_GAR_LENGTH);

  if (status == HAL_OK)
  {
    status = w5500_write_common_registers(
      W5500_SUBR_ADDRESS, g_w5500_net_subnet, W5500_SUBR_LENGTH);
  }
  if (status == HAL_OK)
  {
    status = w5500_write_common_registers(
      W5500_SHAR_ADDRESS, g_w5500_net_mac, W5500_SHAR_LENGTH);
  }
  if (status == HAL_OK)
  {
    status = w5500_write_common_registers(
      W5500_SIPR_ADDRESS, g_w5500_net_ip, W5500_SIPR_LENGTH);
  }

  return status;
}

static HAL_StatusTypeDef w5500_read_network_config(void)
{
  HAL_StatusTypeDef status = w5500_read_common_registers(
    W5500_GAR_ADDRESS, g_w5500_gar_readback, W5500_GAR_LENGTH);

  if (status == HAL_OK)
  {
    status = w5500_read_common_registers(
      W5500_SUBR_ADDRESS, g_w5500_subr_readback, W5500_SUBR_LENGTH);
  }
  if (status == HAL_OK)
  {
    status = w5500_read_common_registers(
      W5500_SHAR_ADDRESS, g_w5500_shar_readback, W5500_SHAR_LENGTH);
  }
  if (status == HAL_OK)
  {
    status = w5500_read_common_registers(
      W5500_SIPR_ADDRESS, g_w5500_sipr_readback, W5500_SIPR_LENGTH);
  }

  return status;
}

static uint32_t w5500_network_readback_matches(void)
{
  for (uint16_t index = 0u; index < W5500_GAR_LENGTH; index++)
  {
    if ((g_w5500_gar_readback[index] != g_w5500_net_gateway[index]) ||
        (g_w5500_subr_readback[index] != g_w5500_net_subnet[index]) ||
        (g_w5500_sipr_readback[index] != g_w5500_net_ip[index]))
    {
      return 0u;
    }
  }

  for (uint16_t index = 0u; index < W5500_SHAR_LENGTH; index++)
  {
    if (g_w5500_shar_readback[index] != g_w5500_net_mac[index])
    {
      return 0u;
    }
  }

  return 1u;
}

static HAL_StatusTypeDef w5500_socket0_write_registers(
  uint16_t address,
  const uint8_t *data,
  uint16_t length)
{
  uint8_t tx[W5500_COMMON_HEADER_LENGTH + W5500_SOCKET0_MAX_DATA_LENGTH];

  if ((data == NULL) || (length == 0u) ||
      (length > W5500_SOCKET0_MAX_DATA_LENGTH))
  {
    return HAL_ERROR;
  }

  tx[0] = (uint8_t)(address >> 8);
  tx[1] = (uint8_t)(address & 0xffu);
  tx[2] = W5500_SOCKET0_WRITE_VDM;
  for (uint16_t index = 0u; index < length; index++)
  {
    tx[W5500_COMMON_HEADER_LENGTH + index] = data[index];
  }

  HAL_GPIO_WritePin(W5500_CS_GPIO_Port, W5500_CS_Pin, GPIO_PIN_RESET);
  const HAL_StatusTypeDef status = HAL_SPI_Transmit(
    &hspi2,
    tx,
    (uint16_t)(W5500_COMMON_HEADER_LENGTH + length),
    W5500_SPI_TIMEOUT_MS);
  HAL_GPIO_WritePin(W5500_CS_GPIO_Port, W5500_CS_Pin, GPIO_PIN_SET);

  return status;
}

static HAL_StatusTypeDef w5500_socket0_read_register(
  uint16_t address,
  uint8_t *value)
{
  const uint8_t tx[4] = {
    (uint8_t)(address >> 8),
    (uint8_t)(address & 0xffu),
    W5500_SOCKET0_READ_VDM,
    0u
  };
  uint8_t rx[4] = {0u};

  if (value == NULL)
  {
    return HAL_ERROR;
  }

  HAL_GPIO_WritePin(W5500_CS_GPIO_Port, W5500_CS_Pin, GPIO_PIN_RESET);
  const HAL_StatusTypeDef status = HAL_SPI_TransmitReceive(
    &hspi2, tx, rx, (uint16_t)sizeof(tx), W5500_SPI_TIMEOUT_MS);
  HAL_GPIO_WritePin(W5500_CS_GPIO_Port, W5500_CS_Pin, GPIO_PIN_SET);

  if (status == HAL_OK)
  {
    *value = rx[3];
  }

  return status;
}

static HAL_StatusTypeDef w5500_socket0_execute_command(uint8_t command)
{
  HAL_StatusTypeDef status = w5500_socket0_write_registers(
    W5500_SOCKET0_CR_ADDRESS, &command, 1u);
  if (status != HAL_OK)
  {
    return status;
  }

  const uint32_t timeout_ticks =
    rs422_ms_to_kernel_ticks(W5500_SOCKET_COMMAND_TIMEOUT_MS);
  const uint32_t poll_ticks =
    rs422_ms_to_kernel_ticks(W5500_SOCKET_COMMAND_POLL_MS);
  const uint32_t start_tick = osKernelGetTickCount();

  for (;;)
  {
    uint8_t command_register = command;
    status = w5500_socket0_read_register(
      W5500_SOCKET0_CR_ADDRESS, &command_register);
    if (status != HAL_OK)
    {
      return status;
    }
    if (command_register == 0u)
    {
      return HAL_OK;
    }
    if ((uint32_t)(osKernelGetTickCount() - start_tick) >= timeout_ticks)
    {
      return HAL_TIMEOUT;
    }

    (void)osDelay(poll_ticks);
  }
}

static HAL_StatusTypeDef w5500_socket0_read_registers(
  uint16_t address,
  uint8_t *data,
  uint16_t length)
{
  uint8_t tx[W5500_COMMON_HEADER_LENGTH + W5500_SOCKET0_MAX_DATA_LENGTH] = {0u};
  uint8_t rx[W5500_COMMON_HEADER_LENGTH + W5500_SOCKET0_MAX_DATA_LENGTH] = {0u};

  if ((data == NULL) || (length == 0u) ||
      (length > W5500_SOCKET0_MAX_DATA_LENGTH))
  {
    return HAL_ERROR;
  }

  tx[0] = (uint8_t)(address >> 8);
  tx[1] = (uint8_t)(address & 0xffu);
  tx[2] = W5500_SOCKET0_READ_VDM;

  HAL_GPIO_WritePin(W5500_CS_GPIO_Port, W5500_CS_Pin, GPIO_PIN_RESET);
  const HAL_StatusTypeDef status = HAL_SPI_TransmitReceive(
    &hspi2,
    tx,
    rx,
    (uint16_t)(W5500_COMMON_HEADER_LENGTH + length),
    W5500_SPI_TIMEOUT_MS);
  HAL_GPIO_WritePin(W5500_CS_GPIO_Port, W5500_CS_Pin, GPIO_PIN_SET);

  if (status == HAL_OK)
  {
    for (uint16_t index = 0u; index < length; index++)
    {
      data[index] = rx[W5500_COMMON_HEADER_LENGTH + index];
    }
  }

  return status;
}

static HAL_StatusTypeDef w5500_socket0_read_u16(
  uint16_t address,
  uint16_t *value)
{
  uint8_t data[2] = {0u};

  if (value == NULL)
  {
    return HAL_ERROR;
  }

  const HAL_StatusTypeDef status = w5500_socket0_read_registers(
    address, data, (uint16_t)sizeof(data));
  if (status == HAL_OK)
  {
    *value = (uint16_t)(((uint16_t)data[0] << 8) | data[1]);
  }

  return status;
}

static HAL_StatusTypeDef w5500_socket0_read_stable_u16(
  uint16_t address,
  uint16_t *value)
{
  uint16_t previous_value = 0u;
  uint16_t current_value = 0u;

  if (value == NULL)
  {
    return HAL_ERROR;
  }

  for (uint32_t attempt = 0u;
       attempt < W5500_TCP_STABLE_READ_ATTEMPTS;
       attempt++)
  {
    const HAL_StatusTypeDef status =
      w5500_socket0_read_u16(address, &current_value);
    if (status != HAL_OK)
    {
      return status;
    }

    if ((attempt != 0u) && (current_value == previous_value))
    {
      *value = current_value;
      return HAL_OK;
    }

    previous_value = current_value;
  }

  /* Do not update the caller's value when no consecutive reads are stable. */
  return HAL_TIMEOUT;
}

static HAL_StatusTypeDef w5500_socket0_write_tx_buffer(
  uint16_t address,
  const uint8_t *data,
  uint16_t length)
{
  const uint8_t header[W5500_COMMON_HEADER_LENGTH] = {
    (uint8_t)(address >> 8),
    (uint8_t)(address & 0xffu),
    W5500_SOCKET0_TX_BUFFER_WRITE_VDM
  };
  uint8_t header_rx[W5500_COMMON_HEADER_LENGTH] = {0u};

  if ((data == NULL) || (length == 0u) ||
      (length > PROTOCOL_MAX_FRAME_SIZE))
  {
    return HAL_ERROR;
  }

  HAL_GPIO_WritePin(W5500_CS_GPIO_Port, W5500_CS_Pin, GPIO_PIN_RESET);
  HAL_StatusTypeDef status = HAL_SPI_TransmitReceive(
    &hspi2,
    header,
    header_rx,
    (uint16_t)sizeof(header),
    W5500_SPI_TIMEOUT_MS);
  uint16_t offset = 0u;
  while ((status == HAL_OK) && (offset < length))
  {
    const uint16_t remaining = (uint16_t)(length - offset);
    const uint16_t chunk_length = (remaining > W5500_TCP_RX_CHUNK_SIZE) ?
      W5500_TCP_RX_CHUNK_SIZE : remaining;
    status = HAL_SPI_TransmitReceive(
      &hspi2,
      &data[offset],
      g_w5500_tcp_rx_dummy,
      chunk_length,
      W5500_SPI_TIMEOUT_MS);
    offset = (uint16_t)(offset + chunk_length);
  }
  HAL_GPIO_WritePin(W5500_CS_GPIO_Port, W5500_CS_Pin, GPIO_PIN_SET);

  return status;
}

static HAL_StatusTypeDef w5500_socket0_read_rx_buffer(
  uint16_t address,
  uint8_t *data,
  uint16_t length)
{
  const uint8_t header[W5500_COMMON_HEADER_LENGTH] = {
    (uint8_t)(address >> 8),
    (uint8_t)(address & 0xffu),
    W5500_SOCKET0_RX_BUFFER_READ_VDM
  };
  uint8_t header_rx[W5500_COMMON_HEADER_LENGTH] = {0u};

  if ((data == NULL) || (length == 0u) ||
      (length > W5500_TCP_RX_CHUNK_SIZE))
  {
    return HAL_ERROR;
  }

  HAL_GPIO_WritePin(W5500_CS_GPIO_Port, W5500_CS_Pin, GPIO_PIN_RESET);
  HAL_StatusTypeDef status = HAL_SPI_TransmitReceive(
    &hspi2,
    header,
    header_rx,
    (uint16_t)sizeof(header),
    W5500_SPI_TIMEOUT_MS);
  if (status == HAL_OK)
  {
    status = HAL_SPI_TransmitReceive(
      &hspi2,
      g_w5500_tcp_rx_dummy,
      data,
      length,
      W5500_SPI_TIMEOUT_MS);
  }
  HAL_GPIO_WritePin(W5500_CS_GPIO_Port, W5500_CS_Pin, GPIO_PIN_SET);

  return status;
}

static HAL_StatusTypeDef w5500_tcp_wait_for_tx_free(
  uint16_t required_size)
{
  const uint32_t timeout_ticks =
    rs422_ms_to_kernel_ticks(W5500_TCP_TX_FREE_TIMEOUT_MS);
  const uint32_t poll_ticks =
    rs422_ms_to_kernel_ticks(W5500_TCP_IO_POLL_MS);
  const uint32_t start_tick = osKernelGetTickCount();

  for (;;)
  {
    uint16_t free_size = 0u;
    const HAL_StatusTypeDef status = w5500_socket0_read_stable_u16(
      W5500_SOCKET0_TX_FSR_ADDRESS, &free_size);
    if (status != HAL_OK)
    {
      return status;
    }
    if (free_size >= required_size)
    {
      return HAL_OK;
    }
    if ((uint32_t)(osKernelGetTickCount() - start_tick) >= timeout_ticks)
    {
      return HAL_TIMEOUT;
    }

    (void)osDelay(poll_ticks);
  }
}

static HAL_StatusTypeDef w5500_tcp_wait_for_send_result(void)
{
  const uint32_t timeout_ticks =
    rs422_ms_to_kernel_ticks(W5500_TCP_SEND_TIMEOUT_MS);
  const uint32_t poll_ticks =
    rs422_ms_to_kernel_ticks(W5500_TCP_IO_POLL_MS);
  const uint32_t start_tick = osKernelGetTickCount();

  for (;;)
  {
    uint8_t socket_interrupt = 0u;
    HAL_StatusTypeDef status = w5500_socket0_read_register(
      W5500_SOCKET0_IR_ADDRESS, &socket_interrupt);
    if (status != HAL_OK)
    {
      return status;
    }

    const uint8_t send_result = (uint8_t)(socket_interrupt &
      (W5500_SOCKET0_IR_SEND_OK | W5500_SOCKET0_IR_TIMEOUT));
    if (send_result != 0u)
    {
      status = w5500_socket0_write_registers(
        W5500_SOCKET0_IR_ADDRESS, &send_result, 1u);
      if (status != HAL_OK)
      {
        return status;
      }

      if ((send_result & W5500_SOCKET0_IR_TIMEOUT) != 0u)
      {
        return HAL_TIMEOUT;
      }
      return HAL_OK;
    }

    if ((uint32_t)(osKernelGetTickCount() - start_tick) >= timeout_ticks)
    {
      return HAL_TIMEOUT;
    }

    (void)osDelay(poll_ticks);
  }
}

static HAL_StatusTypeDef w5500_tcp_send_frame(
  const uint8_t *frame,
  uint16_t frame_length)
{
  if ((frame == NULL) || (frame_length == 0u) ||
      (frame_length > PROTOCOL_MAX_FRAME_SIZE))
  {
    return HAL_ERROR;
  }

  HAL_StatusTypeDef status = w5500_tcp_wait_for_tx_free(frame_length);
  if (status != HAL_OK)
  {
    return status;
  }

  uint16_t tx_write_pointer = 0u;
  status = w5500_socket0_read_u16(
    W5500_SOCKET0_TX_WR_ADDRESS, &tx_write_pointer);
  if (status != HAL_OK)
  {
    return status;
  }

  status = w5500_socket0_write_tx_buffer(
    tx_write_pointer, frame, frame_length);
  if (status != HAL_OK)
  {
    return status;
  }

  const uint16_t new_tx_write_pointer =
    (uint16_t)(tx_write_pointer + frame_length);
  const uint8_t tx_write_pointer_bytes[2] = {
    (uint8_t)(new_tx_write_pointer >> 8),
    (uint8_t)(new_tx_write_pointer & 0xffu)
  };
  status = w5500_socket0_write_registers(
    W5500_SOCKET0_TX_WR_ADDRESS,
    tx_write_pointer_bytes,
    (uint16_t)sizeof(tx_write_pointer_bytes));
  if (status != HAL_OK)
  {
    return status;
  }

  /* Sn_IR is write-one-to-clear. Clear only SEND result bits before SEND. */
  const uint8_t stale_send_bits =
    W5500_SOCKET0_IR_SEND_OK | W5500_SOCKET0_IR_TIMEOUT;
  status = w5500_socket0_write_registers(
    W5500_SOCKET0_IR_ADDRESS, &stale_send_bits, 1u);
  if (status != HAL_OK)
  {
    return status;
  }

  status = w5500_socket0_execute_command(W5500_SOCKET0_SEND_COMMAND);
  if (status != HAL_OK)
  {
    return status;
  }

  return w5500_tcp_wait_for_send_result();
}

static void w5500_tcp_send_response_packet(const protocol_packet_t *packet)
{
  size_t frame_length = 0u;

  if ((packet == NULL) ||
      (protocol_encode(
         packet,
         g_w5500_tcp_tx_frame,
         sizeof(g_w5500_tcp_tx_frame),
         &frame_length) != PROTO_OK) ||
      (frame_length == 0u) ||
      (frame_length > UINT16_MAX))
  {
    g_w5500_tcp_last_tx_status = (int32_t)HAL_ERROR;
    g_w5500_tcp_tx_error_count++;
    return;
  }

  if ((packet->msg_id == MSG_PONG) &&
      (g_diag_first_ping_seq_valid != 0u) &&
      (packet->seq == g_diag_first_ping_seq) &&
      (g_diag_tcp_pong_send_ms == DIAG_TIMESTAMP_NOT_CAPTURED_MS))
  {
    const uint32_t now_ms = diagnostic_now_ms();
    g_diag_tcp_pong_send_ms = now_ms;
    if (g_diag_matching_pong_rx_ms != DIAG_TIMESTAMP_NOT_CAPTURED_MS)
    {
      g_diag_matching_pong_rx_to_tcp_send_ms =
        now_ms - g_diag_matching_pong_rx_ms;
    }
    if (g_diag_tcp_established_ms != DIAG_TIMESTAMP_NOT_CAPTURED_MS)
    {
      g_diag_established_to_tcp_pong_send_ms =
        now_ms - g_diag_tcp_established_ms;
    }
  }

  const HAL_StatusTypeDef status = w5500_tcp_send_frame(
    g_w5500_tcp_tx_frame,
    (uint16_t)frame_length);
  g_w5500_tcp_last_tx_status = (int32_t)status;

  if (status != HAL_OK)
  {
    g_w5500_tcp_tx_error_count++;
    return;
  }

  g_w5500_tcp_tx_bytes += (uint32_t)frame_length;
  g_w5500_tcp_last_tx_msg_id = packet->msg_id;
  g_w5500_tcp_last_tx_seq = packet->seq;
  if (packet->msg_id == MSG_PONG)
  {
    g_w5500_tcp_pong_count++;
    ethernet_diag_record_tcp_pong_tx_success();
  }
}

static void w5500_tcp_handle_valid_frame(void)
{
  g_w5500_tcp_valid_frame_count++;
  g_w5500_tcp_last_rx_msg_id = g_tcp_received_packet.msg_id;
  g_w5500_tcp_last_rx_seq = g_tcp_received_packet.seq;

  if (g_tcp_received_packet.msg_id != MSG_PING)
  {
    return;
  }

  if (g_diag_first_ping_parsed_ms == DIAG_TIMESTAMP_NOT_CAPTURED_MS)
  {
    const uint32_t now_ms = diagnostic_now_ms();
    g_diag_first_ping_seq = g_tcp_received_packet.seq;
    g_diag_first_ping_parsed_ms = now_ms;
    if (g_diag_first_rx_ready_ms != DIAG_TIMESTAMP_NOT_CAPTURED_MS)
    {
      g_diag_rx_ready_to_ping_parsed_ms =
        now_ms - g_diag_first_rx_ready_ms;
    }
    __DMB();
    g_diag_first_ping_seq_valid = 1u;
  }

  g_w5500_tcp_ping_count++;

  if ((rs422_cmd_queue != NULL) &&
      (osMessageQueuePut(
        rs422_cmd_queue,
        &g_tcp_received_packet,
        0u,
        0u) == osOK))
  {
    g_rs422_cmd_enqueue_success_count++;

    if (RS422TaskHandle != NULL)
    {
      (void)osThreadFlagsSet(RS422TaskHandle, RS422_EVENT_CMD_READY);
    }
  }
  else
  {
    g_rs422_cmd_enqueue_fail_count++;
  }
}

static HAL_StatusTypeDef w5500_tcp_process_rx(void)
{
  uint16_t received_size = 0u;
  HAL_StatusTypeDef status = w5500_socket0_read_stable_u16(
    W5500_SOCKET0_RX_RSR_ADDRESS, &received_size);
  if ((status != HAL_OK) || (received_size == 0u))
  {
    return status;
  }

  if (g_diag_first_rx_ready_ms == DIAG_TIMESTAMP_NOT_CAPTURED_MS)
  {
    const uint32_t now_ms = diagnostic_now_ms();
    g_diag_first_rx_ready_ms = now_ms;
    if (g_diag_tcp_established_ms != DIAG_TIMESTAMP_NOT_CAPTURED_MS)
    {
      g_diag_established_to_rx_ready_ms =
        now_ms - g_diag_tcp_established_ms;
    }
  }

  const uint16_t read_length = (received_size > W5500_TCP_RX_CHUNK_SIZE) ?
    W5500_TCP_RX_CHUNK_SIZE : received_size;
  uint16_t rx_read_pointer = 0u;
  status = w5500_socket0_read_u16(
    W5500_SOCKET0_RX_RD_ADDRESS, &rx_read_pointer);
  if (status != HAL_OK)
  {
    return status;
  }

  status = w5500_socket0_read_rx_buffer(
    rx_read_pointer, g_w5500_tcp_rx_chunk, read_length);
  if (status != HAL_OK)
  {
    return status;
  }

  const uint16_t new_rx_read_pointer =
    (uint16_t)(rx_read_pointer + read_length);
  const uint8_t rx_read_pointer_bytes[2] = {
    (uint8_t)(new_rx_read_pointer >> 8),
    (uint8_t)(new_rx_read_pointer & 0xffu)
  };
  status = w5500_socket0_write_registers(
    W5500_SOCKET0_RX_RD_ADDRESS,
    rx_read_pointer_bytes,
    (uint16_t)sizeof(rx_read_pointer_bytes));
  if (status != HAL_OK)
  {
    return status;
  }

  status = w5500_socket0_execute_command(W5500_SOCKET0_RECV_COMMAND);
  if (status != HAL_OK)
  {
    return status;
  }

  g_w5500_tcp_rx_bytes += read_length;
  for (uint16_t index = 0u; index < read_length; index++)
  {
    const stream_parser_event_t parser_event = stream_parser_feed_byte(
      &g_tcp_parser,
      g_w5500_tcp_rx_chunk[index],
      &g_tcp_received_packet);
    if (parser_event == STREAM_EVENT_FRAME)
    {
      w5500_tcp_handle_valid_frame();
    }
    else if (parser_event == STREAM_EVENT_ERROR)
    {
      g_w5500_tcp_rx_error_count++;
    }
  }

  return HAL_OK;
}

static HAL_StatusTypeDef w5500_wait_for_socket0_status(
  uint8_t expected_status,
  uint32_t timeout_ms)
{
  const uint32_t timeout_ticks = rs422_ms_to_kernel_ticks(timeout_ms);
  const uint32_t poll_ticks =
    rs422_ms_to_kernel_ticks(W5500_SOCKET_STATE_POLL_MS);
  const uint32_t start_tick = osKernelGetTickCount();

  for (;;)
  {
    uint8_t socket_status = W5500_SOCKET0_STATUS_CLOSED;
    const HAL_StatusTypeDef spi_status = w5500_socket0_read_register(
      W5500_SOCKET0_SR_ADDRESS, &socket_status);
    g_w5500_socket0_spi_status = (int32_t)spi_status;

    if (spi_status != HAL_OK)
    {
      return spi_status;
    }

    g_w5500_socket0_status = socket_status;
    if (socket_status == expected_status)
    {
      return HAL_OK;
    }

    if ((uint32_t)(osKernelGetTickCount() - start_tick) >= timeout_ticks)
    {
      return HAL_TIMEOUT;
    }

    (void)osDelay(poll_ticks);
  }
}

static HAL_StatusTypeDef w5500_listen_tcp_server(void)
{
  HAL_StatusTypeDef status = w5500_socket0_execute_command(
    W5500_SOCKET0_LISTEN_COMMAND);
  g_w5500_socket0_spi_status = (int32_t)status;

  if (status == HAL_OK)
  {
    status = w5500_wait_for_socket0_status(
      W5500_SOCKET0_STATUS_LISTEN, W5500_SOCKET_STATE_TIMEOUT_MS);
  }

  g_w5500_socket0_spi_status = (int32_t)status;
  if (status == HAL_OK)
  {
    g_w5500_tcp_listen_ok = 1u;
    ethernet_diag_record_tcp_service_ready();
  }

  return status;
}

static HAL_StatusTypeDef w5500_start_tcp_server(void)
{
  const uint8_t tcp_mode = W5500_SOCKET0_TCP_MODE;
  const uint8_t server_port[2] = {
    (uint8_t)(W5500_TCP_SERVER_PORT >> 8),
    (uint8_t)(W5500_TCP_SERVER_PORT & 0xffu)
  };

  g_w5500_tcp_init_ok = 0u;
  g_w5500_tcp_listen_ok = 0u;

  HAL_StatusTypeDef status = w5500_socket0_write_registers(
    W5500_SOCKET0_MR_ADDRESS, &tcp_mode, 1u);
  g_w5500_socket0_spi_status = (int32_t)status;

  if (status == HAL_OK)
  {
    status = w5500_socket0_write_registers(
      W5500_SOCKET0_PORT_ADDRESS, server_port, (uint16_t)sizeof(server_port));
    g_w5500_socket0_spi_status = (int32_t)status;
  }
  if (status == HAL_OK)
  {
    status = w5500_socket0_execute_command(W5500_SOCKET0_OPEN_COMMAND);
    g_w5500_socket0_spi_status = (int32_t)status;
  }
  if (status == HAL_OK)
  {
    status = w5500_wait_for_socket0_status(
      W5500_SOCKET0_STATUS_INIT, W5500_SOCKET_STATE_TIMEOUT_MS);
  }
  if (status != HAL_OK)
  {
    g_w5500_socket0_spi_status = (int32_t)status;
    return status;
  }

  g_w5500_tcp_init_ok = 1u;
  status = w5500_listen_tcp_server();
  return status;
}

static void w5500_tcp_discard_stale_responses(void)
{
  if (tcp_response_queue == NULL)
  {
    return;
  }

  for (uint32_t index = 0u; index < TCP_RESPONSE_QUEUE_DEPTH; index++)
  {
    if (osMessageQueueGet(
          tcp_response_queue,
          &g_tcp_pong_packet,
          NULL,
          0u) != osOK)
    {
      break;
    }

    g_w5500_tcp_stale_response_drop_count++;
  }
}

static void w5500_tcp_drain_response_queue(void)
{
  if (tcp_response_queue == NULL)
  {
    return;
  }

  /* The queue is the data source; the thread flag only wakes this task. */
  for (uint32_t index = 0u; index < TCP_RESPONSE_QUEUE_DEPTH; index++)
  {
    if (osMessageQueueGet(
          tcp_response_queue,
          &g_tcp_pong_packet,
          NULL,
          0u) != osOK)
    {
      break;
    }

    g_tcp_response_dequeue_count++;
    w5500_tcp_send_response_packet(&g_tcp_pong_packet);
  }
}

static void w5500_tcp_invalidate_connection_context(void)
{
  g_w5500_tcp_session_active = 0u;
  __DMB();
  stream_parser_init(&g_tcp_parser);

  if (RS422TaskHandle != NULL)
  {
    (void)osThreadFlagsSet(
      RS422TaskHandle, RS422_EVENT_TCP_CONTEXT_RESET);
  }

  w5500_tcp_discard_stale_responses();
}

static HAL_StatusTypeDef w5500_restart_tcp_server(void)
{
  g_w5500_tcp_init_ok = 0u;
  g_w5500_tcp_listen_ok = 0u;
  w5500_tcp_invalidate_connection_context();

  HAL_StatusTypeDef status = w5500_socket0_execute_command(
    W5500_SOCKET0_CLOSE_COMMAND);
  g_w5500_socket0_spi_status = (int32_t)status;

  if (status == HAL_OK)
  {
    status = w5500_wait_for_socket0_status(
      W5500_SOCKET0_STATUS_CLOSED, W5500_SOCKET_STATE_TIMEOUT_MS);
  }
  if (status == HAL_OK)
  {
    status = w5500_start_tcp_server();
  }

  g_w5500_socket0_spi_status = (int32_t)status;
  w5500_tcp_discard_stale_responses();
  return status;
}

static uint32_t w5500_tcp_is_transient_state(uint8_t socket_status)
{
  switch (socket_status)
  {
    case W5500_SOCKET0_STATUS_SYNSENT:
    case W5500_SOCKET0_STATUS_SYNRECV:
    case W5500_SOCKET0_STATUS_FIN_WAIT:
    case W5500_SOCKET0_STATUS_CLOSING:
    case W5500_SOCKET0_STATUS_TIME_WAIT:
    case W5500_SOCKET0_STATUS_LAST_ACK:
      return 1u;

    default:
      return 0u;
  }
}

static HAL_StatusTypeDef w5500_socket1_write_registers(
  uint16_t address,
  const uint8_t *data,
  uint16_t length)
{
  uint8_t tx[W5500_COMMON_HEADER_LENGTH + W5500_SOCKET1_MAX_DATA_LENGTH];

  if ((data == NULL) || (length == 0u) ||
      (length > W5500_SOCKET1_MAX_DATA_LENGTH))
  {
    return HAL_ERROR;
  }

  tx[0] = (uint8_t)(address >> 8);
  tx[1] = (uint8_t)(address & 0xffu);
  tx[2] = W5500_SOCKET1_WRITE_VDM;
  for (uint16_t index = 0u; index < length; index++)
  {
    tx[W5500_COMMON_HEADER_LENGTH + index] = data[index];
  }

  HAL_GPIO_WritePin(W5500_CS_GPIO_Port, W5500_CS_Pin, GPIO_PIN_RESET);
  const HAL_StatusTypeDef status = HAL_SPI_Transmit(
    &hspi2,
    tx,
    (uint16_t)(W5500_COMMON_HEADER_LENGTH + length),
    W5500_SPI_TIMEOUT_MS);
  HAL_GPIO_WritePin(W5500_CS_GPIO_Port, W5500_CS_Pin, GPIO_PIN_SET);

  return status;
}

static HAL_StatusTypeDef w5500_socket1_read_register(
  uint16_t address,
  uint8_t *value)
{
  const uint8_t tx[4] = {
    (uint8_t)(address >> 8),
    (uint8_t)(address & 0xffu),
    W5500_SOCKET1_READ_VDM,
    0u
  };
  uint8_t rx[4] = {0u};

  if (value == NULL)
  {
    return HAL_ERROR;
  }

  HAL_GPIO_WritePin(W5500_CS_GPIO_Port, W5500_CS_Pin, GPIO_PIN_RESET);
  const HAL_StatusTypeDef status = HAL_SPI_TransmitReceive(
    &hspi2, tx, rx, (uint16_t)sizeof(tx), W5500_SPI_TIMEOUT_MS);
  HAL_GPIO_WritePin(W5500_CS_GPIO_Port, W5500_CS_Pin, GPIO_PIN_SET);

  if (status == HAL_OK)
  {
    *value = rx[3];
  }

  return status;
}

static HAL_StatusTypeDef w5500_socket1_read_registers(
  uint16_t address,
  uint8_t *data,
  uint16_t length)
{
  uint8_t tx[W5500_COMMON_HEADER_LENGTH + W5500_SOCKET1_MAX_DATA_LENGTH] = {0u};
  uint8_t rx[W5500_COMMON_HEADER_LENGTH + W5500_SOCKET1_MAX_DATA_LENGTH] = {0u};

  if ((data == NULL) || (length == 0u) ||
      (length > W5500_SOCKET1_MAX_DATA_LENGTH))
  {
    return HAL_ERROR;
  }

  tx[0] = (uint8_t)(address >> 8);
  tx[1] = (uint8_t)(address & 0xffu);
  tx[2] = W5500_SOCKET1_READ_VDM;

  HAL_GPIO_WritePin(W5500_CS_GPIO_Port, W5500_CS_Pin, GPIO_PIN_RESET);
  const HAL_StatusTypeDef status = HAL_SPI_TransmitReceive(
    &hspi2,
    tx,
    rx,
    (uint16_t)(W5500_COMMON_HEADER_LENGTH + length),
    W5500_SPI_TIMEOUT_MS);
  HAL_GPIO_WritePin(W5500_CS_GPIO_Port, W5500_CS_Pin, GPIO_PIN_SET);

  if (status == HAL_OK)
  {
    for (uint16_t index = 0u; index < length; index++)
    {
      data[index] = rx[W5500_COMMON_HEADER_LENGTH + index];
    }
  }

  return status;
}

static HAL_StatusTypeDef w5500_socket1_read_u16(
  uint16_t address,
  uint16_t *value)
{
  uint8_t data[2] = {0u};

  if (value == NULL)
  {
    return HAL_ERROR;
  }

  const HAL_StatusTypeDef status = w5500_socket1_read_registers(
    address, data, (uint16_t)sizeof(data));
  if (status == HAL_OK)
  {
    *value = (uint16_t)(((uint16_t)data[0] << 8) | data[1]);
  }

  return status;
}

static HAL_StatusTypeDef w5500_socket1_read_stable_u16(
  uint16_t address,
  uint16_t *value)
{
  uint16_t previous_value = 0u;
  uint16_t current_value = 0u;

  if (value == NULL)
  {
    return HAL_ERROR;
  }

  for (uint32_t attempt = 0u;
       attempt < W5500_UDP_STABLE_READ_ATTEMPTS;
       attempt++)
  {
    const HAL_StatusTypeDef status =
      w5500_socket1_read_u16(address, &current_value);
    if (status != HAL_OK)
    {
      return status;
    }

    if ((attempt != 0u) && (current_value == previous_value))
    {
      *value = current_value;
      return HAL_OK;
    }

    previous_value = current_value;
  }

  /* Leave the caller's value unchanged if no consecutive samples agree. */
  return HAL_TIMEOUT;
}

static HAL_StatusTypeDef w5500_socket1_write_tx_buffer(
  uint16_t address,
  const uint8_t *data,
  uint16_t length)
{
  const uint8_t header[W5500_COMMON_HEADER_LENGTH] = {
    (uint8_t)(address >> 8),
    (uint8_t)(address & 0xffu),
    W5500_SOCKET1_TX_BUFFER_WRITE_VDM
  };
  uint8_t header_rx[W5500_COMMON_HEADER_LENGTH] = {0u};

  if ((data == NULL) || (length == 0u) ||
      (length > PROTOCOL_MAX_FRAME_SIZE))
  {
    return HAL_ERROR;
  }

  HAL_GPIO_WritePin(W5500_CS_GPIO_Port, W5500_CS_Pin, GPIO_PIN_RESET);
  HAL_StatusTypeDef status = HAL_SPI_TransmitReceive(
    &hspi2,
    header,
    header_rx,
    (uint16_t)sizeof(header),
    W5500_SPI_TIMEOUT_MS);
  uint16_t offset = 0u;
  while ((status == HAL_OK) && (offset < length))
  {
    const uint16_t remaining = (uint16_t)(length - offset);
    const uint16_t chunk_length = (remaining > W5500_UDP_SPI_CHUNK_SIZE) ?
      W5500_UDP_SPI_CHUNK_SIZE : remaining;
    status = HAL_SPI_TransmitReceive(
      &hspi2,
      &data[offset],
      g_w5500_udp_spi_discard,
      chunk_length,
      W5500_SPI_TIMEOUT_MS);
    offset = (uint16_t)(offset + chunk_length);
  }
  HAL_GPIO_WritePin(W5500_CS_GPIO_Port, W5500_CS_Pin, GPIO_PIN_SET);

  return status;
}

static HAL_StatusTypeDef w5500_socket1_execute_command(uint8_t command)
{
  HAL_StatusTypeDef status = w5500_socket1_write_registers(
    W5500_SOCKET1_CR_ADDRESS, &command, 1u);
  if (status != HAL_OK)
  {
    return status;
  }

  const uint32_t timeout_ticks =
    rs422_ms_to_kernel_ticks(W5500_SOCKET_COMMAND_TIMEOUT_MS);
  const uint32_t poll_ticks =
    rs422_ms_to_kernel_ticks(W5500_SOCKET_COMMAND_POLL_MS);
  const uint32_t start_tick = osKernelGetTickCount();

  for (;;)
  {
    uint8_t command_register = command;
    status = w5500_socket1_read_register(
      W5500_SOCKET1_CR_ADDRESS, &command_register);
    if (status != HAL_OK)
    {
      return status;
    }
    if (command_register == 0u)
    {
      return HAL_OK;
    }
    if ((uint32_t)(osKernelGetTickCount() - start_tick) >= timeout_ticks)
    {
      return HAL_TIMEOUT;
    }

    (void)osDelay(poll_ticks);
  }
}

static HAL_StatusTypeDef w5500_wait_for_socket1_status(
  uint8_t expected_status,
  uint32_t timeout_ms)
{
  const uint32_t timeout_ticks = rs422_ms_to_kernel_ticks(timeout_ms);
  const uint32_t poll_ticks =
    rs422_ms_to_kernel_ticks(W5500_SOCKET_STATE_POLL_MS);
  const uint32_t start_tick = osKernelGetTickCount();

  for (;;)
  {
    uint8_t socket_status = W5500_SOCKET1_STATUS_CLOSED;
    const HAL_StatusTypeDef spi_status = w5500_socket1_read_register(
      W5500_SOCKET1_SR_ADDRESS, &socket_status);
    g_w5500_udp_socket1_spi_status = (int32_t)spi_status;

    if (spi_status != HAL_OK)
    {
      return spi_status;
    }

    g_w5500_udp_socket1_status = socket_status;
    if (socket_status == expected_status)
    {
      return HAL_OK;
    }
    if ((uint32_t)(osKernelGetTickCount() - start_tick) >= timeout_ticks)
    {
      return HAL_TIMEOUT;
    }

    (void)osDelay(poll_ticks);
  }
}

static HAL_StatusTypeDef w5500_udp_wait_for_tx_free(
  uint16_t required_size)
{
  const uint32_t timeout_ticks =
    rs422_ms_to_kernel_ticks(W5500_UDP_TX_FREE_TIMEOUT_MS);
  const uint32_t poll_ticks =
    rs422_ms_to_kernel_ticks(W5500_UDP_IO_POLL_MS);
  const uint32_t start_tick = osKernelGetTickCount();

  for (;;)
  {
    uint16_t free_size = 0u;
    const HAL_StatusTypeDef status = w5500_socket1_read_stable_u16(
      W5500_SOCKET1_TX_FSR_ADDRESS, &free_size);
    if (status != HAL_OK)
    {
      return status;
    }
    if (free_size >= required_size)
    {
      return HAL_OK;
    }
    if ((uint32_t)(osKernelGetTickCount() - start_tick) >= timeout_ticks)
    {
      return HAL_TIMEOUT;
    }

    (void)osDelay(poll_ticks);
  }
}

static HAL_StatusTypeDef w5500_udp_wait_for_send_result(void)
{
  const uint32_t timeout_ticks =
    rs422_ms_to_kernel_ticks(W5500_UDP_SEND_TIMEOUT_MS);
  const uint32_t poll_ticks =
    rs422_ms_to_kernel_ticks(W5500_UDP_IO_POLL_MS);
  const uint32_t start_tick = osKernelGetTickCount();

  for (;;)
  {
    uint8_t socket_interrupt = 0u;
    HAL_StatusTypeDef status = w5500_socket1_read_register(
      W5500_SOCKET1_IR_ADDRESS, &socket_interrupt);
    if (status != HAL_OK)
    {
      return status;
    }

    const uint8_t send_result = (uint8_t)(socket_interrupt &
      (W5500_SOCKET1_IR_SEND_OK | W5500_SOCKET1_IR_TIMEOUT));
    if (send_result != 0u)
    {
      status = w5500_socket1_write_registers(
        W5500_SOCKET1_IR_ADDRESS, &send_result, 1u);
      if (status != HAL_OK)
      {
        return status;
      }

      if ((send_result & W5500_SOCKET1_IR_TIMEOUT) != 0u)
      {
        return HAL_TIMEOUT;
      }
      return HAL_OK;
    }

    if ((uint32_t)(osKernelGetTickCount() - start_tick) >= timeout_ticks)
    {
      return HAL_TIMEOUT;
    }

    (void)osDelay(poll_ticks);
  }
}

static HAL_StatusTypeDef w5500_udp_send_frame(
  const uint8_t *frame,
  uint16_t frame_length)
{
  if ((frame == NULL) || (frame_length == 0u) ||
      (frame_length > PROTOCOL_MAX_FRAME_SIZE))
  {
    return HAL_ERROR;
  }

  HAL_StatusTypeDef status = w5500_udp_wait_for_tx_free(frame_length);
  if (status != HAL_OK)
  {
    return status;
  }

  uint16_t tx_write_pointer = 0u;
  status = w5500_socket1_read_u16(
    W5500_SOCKET1_TX_WR_ADDRESS, &tx_write_pointer);
  if (status != HAL_OK)
  {
    return status;
  }

  status = w5500_socket1_write_tx_buffer(
    tx_write_pointer, frame, frame_length);
  if (status != HAL_OK)
  {
    return status;
  }

  const uint16_t new_tx_write_pointer =
    (uint16_t)(tx_write_pointer + frame_length);
  const uint8_t tx_write_pointer_bytes[2] = {
    (uint8_t)(new_tx_write_pointer >> 8),
    (uint8_t)(new_tx_write_pointer & 0xffu)
  };
  status = w5500_socket1_write_registers(
    W5500_SOCKET1_TX_WR_ADDRESS,
    tx_write_pointer_bytes,
    (uint16_t)sizeof(tx_write_pointer_bytes));
  if (status != HAL_OK)
  {
    return status;
  }

  /* Sn_IR is write-one-to-clear. Remove stale SEND result before SEND. */
  const uint8_t stale_send_bits =
    W5500_SOCKET1_IR_SEND_OK | W5500_SOCKET1_IR_TIMEOUT;
  status = w5500_socket1_write_registers(
    W5500_SOCKET1_IR_ADDRESS, &stale_send_bits, 1u);
  if (status != HAL_OK)
  {
    return status;
  }

  status = w5500_socket1_execute_command(W5500_SOCKET1_SEND_COMMAND);
  if (status != HAL_OK)
  {
    return status;
  }

  return w5500_udp_wait_for_send_result();
}

static HAL_StatusTypeDef w5500_start_udp_socket(void)
{
  const uint8_t udp_mode = W5500_SOCKET1_UDP_MODE;
  const uint8_t local_port[2] = {
    (uint8_t)(W5500_UDP_LOCAL_PORT >> 8),
    (uint8_t)(W5500_UDP_LOCAL_PORT & 0xffu)
  };
  const uint8_t destination_port[2] = {
    (uint8_t)(W5500_UDP_DESTINATION_PORT >> 8),
    (uint8_t)(W5500_UDP_DESTINATION_PORT & 0xffu)
  };

  HAL_StatusTypeDef status = w5500_socket1_write_registers(
    W5500_SOCKET1_MR_ADDRESS, &udp_mode, 1u);
  if (status == HAL_OK)
  {
    status = w5500_socket1_write_registers(
      W5500_SOCKET1_PORT_ADDRESS,
      local_port,
      (uint16_t)sizeof(local_port));
  }
  if (status == HAL_OK)
  {
    status = w5500_socket1_execute_command(W5500_SOCKET1_OPEN_COMMAND);
  }
  if (status == HAL_OK)
  {
    status = w5500_wait_for_socket1_status(
      W5500_SOCKET1_STATUS_UDP, W5500_SOCKET_STATE_TIMEOUT_MS);
  }
  if (status == HAL_OK)
  {
    status = w5500_socket1_write_registers(
      W5500_SOCKET1_DIPR_ADDRESS,
      g_w5500_udp_destination_ip,
      (uint16_t)sizeof(g_w5500_udp_destination_ip));
  }
  if (status == HAL_OK)
  {
    status = w5500_socket1_write_registers(
      W5500_SOCKET1_DPORT_ADDRESS,
      destination_port,
      (uint16_t)sizeof(destination_port));
  }

  return status;
}

static uint32_t w5500_kernel_uptime_ms(void)
{
  const uint32_t tick_frequency = osKernelGetTickFreq();
  if (tick_frequency == 0u)
  {
    return 0u;
  }

  return (uint32_t)(((uint64_t)osKernelGetTickCount() * 1000u) /
                    tick_frequency);
}

static void w5500_udp_send_telemetry(void)
{
  const uint16_t sequence = g_w5500_udp_next_seq;
  const uint32_t uptime_ms = w5500_kernel_uptime_ms();

  g_udp_telemetry_packet.version = PROTOCOL_VERSION;
  g_udp_telemetry_packet.msg_id = MSG_TELEMETRY;
  g_udp_telemetry_packet.seq = sequence;
  g_udp_telemetry_packet.length = W5500_UDP_PAYLOAD_LENGTH;
  g_udp_telemetry_packet.payload[0] = (uint8_t)(uptime_ms >> 24);
  g_udp_telemetry_packet.payload[1] = (uint8_t)(uptime_ms >> 16);
  g_udp_telemetry_packet.payload[2] = (uint8_t)(uptime_ms >> 8);
  g_udp_telemetry_packet.payload[3] = (uint8_t)(uptime_ms & 0xffu);
  g_udp_telemetry_packet.payload[4] = 0u;
  g_udp_telemetry_packet.payload[5] = 0u;

  size_t encoded_length = 0u;
  const protocol_result_t encode_status = protocol_encode(
    &g_udp_telemetry_packet,
    g_w5500_udp_tx_frame,
    sizeof(g_w5500_udp_tx_frame),
    &encoded_length);
  if ((encode_status != PROTO_OK) || (encoded_length == 0u) ||
      (encoded_length > UINT16_MAX))
  {
    g_w5500_udp_last_tx_status = (int32_t)encode_status;
    g_w5500_udp_tx_error_count++;
    return;
  }

  const HAL_StatusTypeDef send_status = w5500_udp_send_frame(
    g_w5500_udp_tx_frame, (uint16_t)encoded_length);
  g_w5500_udp_last_tx_status = (int32_t)send_status;
  g_w5500_udp_socket1_spi_status = (int32_t)send_status;

  if (send_status == HAL_OK)
  {
    g_w5500_udp_tx_packet_count++;
    g_w5500_udp_tx_bytes += (uint32_t)encoded_length;
    g_w5500_udp_last_tx_seq = sequence;
    g_w5500_udp_next_seq = (uint16_t)(sequence + 1u);
  }
  else
  {
    g_w5500_udp_tx_error_count++;
  }
}

static HAL_StatusTypeDef w5500_udp_forward_packet(
  const protocol_packet_t *packet)
{
  size_t encoded_length = 0u;

  if ((packet == NULL) || (packet->msg_id != MSG_TELEMETRY))
  {
    g_w5500_udp_last_tx_status = (int32_t)HAL_ERROR;
    g_w5500_udp_tx_error_count++;
    return HAL_ERROR;
  }

  const protocol_result_t encode_status = protocol_encode(
    packet,
    g_w5500_udp_tx_frame,
    sizeof(g_w5500_udp_tx_frame),
    &encoded_length);
  if ((encode_status != PROTO_OK) || (encoded_length == 0u) ||
      (encoded_length > UINT16_MAX))
  {
    g_w5500_udp_last_tx_status = (int32_t)encode_status;
    g_w5500_udp_tx_error_count++;
    return HAL_ERROR;
  }

  const HAL_StatusTypeDef send_status = w5500_udp_send_frame(
    g_w5500_udp_tx_frame, (uint16_t)encoded_length);
  g_w5500_udp_last_tx_status = (int32_t)send_status;
  g_w5500_udp_socket1_spi_status = (int32_t)send_status;

  if (send_status == HAL_OK)
  {
    g_w5500_udp_tx_packet_count++;
    g_w5500_udp_tx_bytes += (uint32_t)encoded_length;
    g_w5500_udp_last_tx_seq = packet->seq;
    ethernet_diag_record_udp_tx_success();
  }
  else
  {
    g_w5500_udp_tx_error_count++;
  }

  return send_status;
}

static void rs422_rx_ring_push_from_isr(uint8_t byte)
{
  const uint16_t head = g_rs422_rx_head;
  const uint16_t tail = g_rs422_rx_tail;

  if ((uint16_t)(head - tail) >= RS422_RX_RING_CAPACITY)
  {
    g_rs422_rx_overflow_count++;
    return;
  }

  g_rs422_rx_ring[head & RS422_RX_RING_MASK] = byte;
  __DMB();
  g_rs422_rx_head = (uint16_t)(head + 1u);
}

static uint32_t rs422_rx_ring_pop(uint8_t *byte)
{
  const uint16_t tail = g_rs422_rx_tail;

  if (tail == g_rs422_rx_head)
  {
    return 0u;
  }

  __DMB();
  *byte = g_rs422_rx_ring[tail & RS422_RX_RING_MASK];
  __DMB();
  g_rs422_rx_tail = (uint16_t)(tail + 1u);
  return 1u;
}

static uint32_t rs422_ms_to_kernel_ticks(uint32_t time_ms)
{
  const uint32_t tick_frequency = osKernelGetTickFreq();
  uint32_t ticks = (uint32_t)((((uint64_t)time_ms * tick_frequency) + 999u) /
                              1000u);

  if (ticks == 0u)
  {
    ticks = 1u;
  }

  return ticks;
}

static uint32_t rs422_kernel_ticks_to_ms(uint32_t ticks)
{
  const uint32_t tick_frequency = osKernelGetTickFreq();

  if (tick_frequency == 0u)
  {
    return DIAG_TIMESTAMP_NOT_CAPTURED_MS;
  }

  return (uint32_t)(((uint64_t)ticks * 1000u) / tick_frequency);
}

static void rs422_diag_record_timeout_transition(
  uint32_t timeout_tick,
  uint32_t has_valid_frame,
  uint32_t last_valid_frame_tick)
{
  g_rs422_diag_timeout_transition_tick = timeout_tick;
  g_rs422_diag_timeout_transition_ms =
    rs422_kernel_ticks_to_ms(timeout_tick);
  g_rs422_diag_fault_detection_ms = DIAG_TIMESTAMP_NOT_CAPTURED_MS;

  if (has_valid_frame != 0u)
  {
    const uint32_t fault_detection_ticks =
      timeout_tick - last_valid_frame_tick;
    g_rs422_diag_fault_detection_ms =
      rs422_kernel_ticks_to_ms(fault_detection_ticks);
  }

  g_rs422_diag_recovery_first_valid_tick = UINT32_MAX;
  g_rs422_diag_recovery_comm_ok_tick = UINT32_MAX;
  g_rs422_diag_recovery_first_valid_ms =
    DIAG_TIMESTAMP_NOT_CAPTURED_MS;
  g_rs422_diag_recovery_comm_ok_ms =
    DIAG_TIMESTAMP_NOT_CAPTURED_MS;
  g_rs422_diag_recovery_ms = DIAG_TIMESTAMP_NOT_CAPTURED_MS;
  __DMB();
}

static void ethernet_diag_initialize(void)
{
  g_eth_diag_recovery_cycle_active = 0u;
  g_eth_diag_link_down_tick = UINT32_MAX;
  g_eth_diag_link_up_tick = UINT32_MAX;
  g_eth_diag_tcp_service_ready_tick = UINT32_MAX;
  g_eth_diag_first_tcp_pong_tx_success_tick = UINT32_MAX;
  g_eth_diag_first_udp_tx_success_tick = UINT32_MAX;
  g_eth_diag_link_down_observed_ms = DIAG_TIMESTAMP_NOT_CAPTURED_MS;
  g_eth_diag_link_up_observed_ms = DIAG_TIMESTAMP_NOT_CAPTURED_MS;
  g_eth_diag_tcp_service_ready_ms = DIAG_TIMESTAMP_NOT_CAPTURED_MS;
  g_eth_diag_first_tcp_pong_tx_success_ms =
    DIAG_TIMESTAMP_NOT_CAPTURED_MS;
  g_eth_diag_first_udp_tx_success_ms = DIAG_TIMESTAMP_NOT_CAPTURED_MS;
  g_eth_diag_linkup_to_tcp_service_ready_ms =
    DIAG_TIMESTAMP_NOT_CAPTURED_MS;
  g_eth_diag_linkup_to_tcp_pong_tx_ms =
    DIAG_TIMESTAMP_NOT_CAPTURED_MS;
  g_eth_diag_linkup_to_udp_tx_ms = DIAG_TIMESTAMP_NOT_CAPTURED_MS;
}

static void ethernet_diag_arm_recovery(uint32_t link_down_tick)
{
  g_eth_diag_recovery_cycle_active = 0u;
  __DMB();

  g_eth_diag_link_down_tick = link_down_tick;
  g_eth_diag_link_up_tick = UINT32_MAX;
  g_eth_diag_tcp_service_ready_tick = UINT32_MAX;
  g_eth_diag_first_tcp_pong_tx_success_tick = UINT32_MAX;
  g_eth_diag_first_udp_tx_success_tick = UINT32_MAX;
  g_eth_diag_link_down_observed_ms =
    rs422_kernel_ticks_to_ms(link_down_tick);
  g_eth_diag_link_up_observed_ms = DIAG_TIMESTAMP_NOT_CAPTURED_MS;
  g_eth_diag_tcp_service_ready_ms = DIAG_TIMESTAMP_NOT_CAPTURED_MS;
  g_eth_diag_first_tcp_pong_tx_success_ms =
    DIAG_TIMESTAMP_NOT_CAPTURED_MS;
  g_eth_diag_first_udp_tx_success_ms = DIAG_TIMESTAMP_NOT_CAPTURED_MS;
  g_eth_diag_linkup_to_tcp_service_ready_ms =
    DIAG_TIMESTAMP_NOT_CAPTURED_MS;
  g_eth_diag_linkup_to_tcp_pong_tx_ms =
    DIAG_TIMESTAMP_NOT_CAPTURED_MS;
  g_eth_diag_linkup_to_udp_tx_ms = DIAG_TIMESTAMP_NOT_CAPTURED_MS;

  __DMB();
  g_eth_diag_recovery_cycle_active = 1u;
}

static void ethernet_diag_record_link_up(uint32_t link_up_tick)
{
  if ((g_eth_diag_recovery_cycle_active == 0u) ||
      (g_eth_diag_link_up_tick != UINT32_MAX))
  {
    return;
  }

  g_eth_diag_link_up_observed_ms =
    rs422_kernel_ticks_to_ms(link_up_tick);
  __DMB();
  g_eth_diag_link_up_tick = link_up_tick;
}

static void ethernet_diag_finish_if_complete(void)
{
  if ((g_eth_diag_tcp_service_ready_tick != UINT32_MAX) &&
      (g_eth_diag_first_tcp_pong_tx_success_tick != UINT32_MAX) &&
      (g_eth_diag_first_udp_tx_success_tick != UINT32_MAX))
  {
    __DMB();
    g_eth_diag_recovery_cycle_active = 0u;
  }
}

static void ethernet_diag_record_tcp_service_ready(void)
{
  const uint32_t link_up_tick = g_eth_diag_link_up_tick;

  if ((g_eth_diag_recovery_cycle_active == 0u) ||
      (link_up_tick == UINT32_MAX) ||
      (g_eth_diag_tcp_service_ready_tick != UINT32_MAX))
  {
    return;
  }

  const uint32_t ready_tick = osKernelGetTickCount();
  const uint32_t elapsed_ticks = ready_tick - link_up_tick;
  g_eth_diag_tcp_service_ready_ms =
    rs422_kernel_ticks_to_ms(ready_tick);
  g_eth_diag_linkup_to_tcp_service_ready_ms =
    rs422_kernel_ticks_to_ms(elapsed_ticks);
  __DMB();
  g_eth_diag_tcp_service_ready_tick = ready_tick;
  ethernet_diag_finish_if_complete();
}

static void ethernet_diag_record_tcp_pong_tx_success(void)
{
  const uint32_t link_up_tick = g_eth_diag_link_up_tick;

  if ((g_eth_diag_recovery_cycle_active == 0u) ||
      (link_up_tick == UINT32_MAX) ||
      (g_eth_diag_first_tcp_pong_tx_success_tick != UINT32_MAX))
  {
    return;
  }

  const uint32_t success_tick = osKernelGetTickCount();
  const uint32_t elapsed_ticks = success_tick - link_up_tick;
  g_eth_diag_first_tcp_pong_tx_success_ms =
    rs422_kernel_ticks_to_ms(success_tick);
  g_eth_diag_linkup_to_tcp_pong_tx_ms =
    rs422_kernel_ticks_to_ms(elapsed_ticks);
  __DMB();
  g_eth_diag_first_tcp_pong_tx_success_tick = success_tick;
  ethernet_diag_finish_if_complete();
}

static void ethernet_diag_record_udp_tx_success(void)
{
  const uint32_t link_up_tick = g_eth_diag_link_up_tick;

  if ((g_eth_diag_recovery_cycle_active == 0u) ||
      (link_up_tick == UINT32_MAX) ||
      (g_eth_diag_first_udp_tx_success_tick != UINT32_MAX))
  {
    return;
  }

  const uint32_t success_tick = osKernelGetTickCount();
  const uint32_t elapsed_ticks = success_tick - link_up_tick;
  g_eth_diag_first_udp_tx_success_ms =
    rs422_kernel_ticks_to_ms(success_tick);
  g_eth_diag_linkup_to_udp_tx_ms =
    rs422_kernel_ticks_to_ms(elapsed_ticks);
  __DMB();
  g_eth_diag_first_udp_tx_success_tick = success_tick;
  ethernet_diag_finish_if_complete();
}

static uint32_t diagnostic_now_ms(void)
{
  /* FreeRTOSConfig.h configures the kernel tick at 1000 Hz. */
  return osKernelGetTickCount();
}

static void diagnostic_begin_tcp_session(uint32_t established_ms)
{
  g_diag_first_ping_seq_valid = 0u;
  __DMB();
  g_diag_tcp_established_ms = established_ms;
  g_diag_first_rx_ready_ms = DIAG_TIMESTAMP_NOT_CAPTURED_MS;
  g_diag_first_ping_parsed_ms = DIAG_TIMESTAMP_NOT_CAPTURED_MS;
  g_diag_rs422_ping_tx_ms = DIAG_TIMESTAMP_NOT_CAPTURED_MS;
  g_diag_matching_pong_rx_ms = DIAG_TIMESTAMP_NOT_CAPTURED_MS;
  g_diag_tcp_pong_send_ms = DIAG_TIMESTAMP_NOT_CAPTURED_MS;
  g_diag_established_to_rx_ready_ms = DIAG_TIMESTAMP_NOT_CAPTURED_MS;
  g_diag_rx_ready_to_ping_parsed_ms = DIAG_TIMESTAMP_NOT_CAPTURED_MS;
  g_diag_ping_parsed_to_rs422_tx_ms = DIAG_TIMESTAMP_NOT_CAPTURED_MS;
  g_diag_rs422_tx_to_matching_pong_rx_ms =
    DIAG_TIMESTAMP_NOT_CAPTURED_MS;
  g_diag_matching_pong_rx_to_tcp_send_ms =
    DIAG_TIMESTAMP_NOT_CAPTURED_MS;
  g_diag_established_to_tcp_pong_send_ms =
    DIAG_TIMESTAMP_NOT_CAPTURED_MS;
  g_diag_first_ping_seq = 0u;
}

static uint32_t rs422_process_rx_buffer(
  uint16_t expected_pong_sequence,
  uint32_t match_pong)
{
  uint8_t rx_byte;
  uint32_t matching_pong_received = 0u;

  while (rs422_rx_ring_pop(&rx_byte) != 0u)
  {
    const stream_parser_event_t parser_event = stream_parser_feed_byte(
      &g_rs422_parser,
      rx_byte,
      &g_rs422_received_packet);

    if (parser_event == STREAM_EVENT_FRAME)
    {
      const rs422_comm_state_t previous_comm_state = g_rs422_comm_state;
      const uint32_t valid_frame_tick = osKernelGetTickCount();

      g_rs422_rx_frame_count++;
      g_rs422_last_msg_id = g_rs422_received_packet.msg_id;
      g_rs422_last_valid_frame_tick = valid_frame_tick;
      g_rs422_diag_last_valid_frame_ms =
        rs422_kernel_ticks_to_ms(valid_frame_tick);

      if ((previous_comm_state == COMM_TIMEOUT) &&
          (g_rs422_diag_recovery_first_valid_tick == UINT32_MAX))
      {
        g_rs422_diag_recovery_first_valid_tick = valid_frame_tick;
        g_rs422_diag_recovery_first_valid_ms =
          rs422_kernel_ticks_to_ms(valid_frame_tick);
      }

      __DMB();
      g_rs422_has_valid_frame = 1u;

      if (g_rs422_received_packet.msg_id == MSG_TELEMETRY)
      {
        g_rs422_telemetry_rx_count++;

        if (g_rs422_telemetry_forwarding_enabled != 0u)
        {
          if ((udp_telemetry_queue != NULL) &&
              (osMessageQueuePut(
                 udp_telemetry_queue,
                 &g_rs422_received_packet,
                 0u,
                 0u) == osOK))
          {
            g_udp_telemetry_enqueue_success_count++;
          }
          else
          {
            g_udp_telemetry_enqueue_fail_count++;
          }
        }
      }

      if ((match_pong != 0u) &&
          (g_rs422_received_packet.msg_id == MSG_PONG) &&
          (g_rs422_received_packet.seq == expected_pong_sequence))
      {
        matching_pong_received = 1u;
      }

      if ((g_rs422_received_packet.msg_id == MSG_PONG) &&
          (g_w5500_tcp_session_active != 0u) &&
          (g_rs422_tcp_ping_pending != 0u) &&
          (g_rs422_received_packet.seq == g_rs422_tcp_ping_pending_seq))
      {
        if ((g_diag_first_ping_seq_valid != 0u) &&
            (g_rs422_received_packet.seq == g_diag_first_ping_seq) &&
            (g_diag_matching_pong_rx_ms ==
             DIAG_TIMESTAMP_NOT_CAPTURED_MS))
        {
          const uint32_t now_ms = diagnostic_now_ms();
          g_diag_matching_pong_rx_ms = now_ms;
          if (g_diag_rs422_ping_tx_ms != DIAG_TIMESTAMP_NOT_CAPTURED_MS)
          {
            g_diag_rs422_tx_to_matching_pong_rx_ms =
              now_ms - g_diag_rs422_ping_tx_ms;
          }
        }

        g_rs422_tcp_ping_pending = 0u;
        g_rs422_forwarded_pong_rx_count++;

        if ((tcp_response_queue != NULL) &&
            (osMessageQueuePut(
               tcp_response_queue,
               &g_rs422_received_packet,
               0u,
               0u) == osOK))
        {
          g_tcp_response_enqueue_success_count++;

          if (EthernetTaskHandle != NULL)
          {
            (void)osThreadFlagsSet(
              EthernetTaskHandle,
              ETHERNET_EVENT_TCP_RESPONSE_READY);
          }
        }
        else
        {
          g_tcp_response_enqueue_fail_count++;
        }
      }
    }
  }

  return matching_pong_received;
}

static void rs422_handle_tcp_context_reset_event(uint32_t flags)
{
  if ((flags & RS422_EVENT_TCP_CONTEXT_RESET) != 0u)
  {
    g_rs422_tcp_ping_pending = 0u;
    g_rs422_tcp_ping_pending_seq = 0u;
  }
}

static void rs422_handle_tx_done_event(uint32_t flags)
{
  if ((flags & RS422_EVENT_TX_DONE) != 0u)
  {
    if (g_rs422_tx_busy != 0u)
    {
      g_rs422_tx_busy = 0u;
      g_rs422_tx_complete_count++;
    }
    else
    {
      g_rs422_tx_error_count++;
    }
  }
}

static int32_t rs422_wait_for_tx_complete(
  uint16_t expected_pong_sequence,
  uint32_t *matching_pong_received)
{
  const uint32_t timeout_ticks =
    rs422_ms_to_kernel_ticks(RS422_BRINGUP_TX_TIMEOUT_MS);
  const uint32_t wait_start_ticks = osKernelGetTickCount();

  *matching_pong_received = 0u;

  while (g_rs422_tx_busy != 0u)
  {
    *matching_pong_received |=
      rs422_process_rx_buffer(expected_pong_sequence, 1u);

    const uint32_t pending_flags = osThreadFlagsWait(
      RS422_EVENT_MASK,
      osFlagsWaitAny,
      0u);

    if ((pending_flags & osFlagsError) == 0u)
    {
      rs422_handle_tcp_context_reset_event(pending_flags);
      rs422_handle_tx_done_event(pending_flags);
    }
    else if (pending_flags != osFlagsErrorResource)
    {
      g_rs422_tx_error_count++;
      return RS422_PING_TEST_TX_FAILURE;
    }

    if (g_rs422_tx_busy == 0u)
    {
      *matching_pong_received |=
        rs422_process_rx_buffer(expected_pong_sequence, 1u);
      return RS422_PING_TEST_PASS;
    }

    const uint32_t elapsed_ticks =
      (uint32_t)(osKernelGetTickCount() - wait_start_ticks);

    if (elapsed_ticks >= timeout_ticks)
    {
      g_rs422_tx_timeout_count++;
      return RS422_PING_TEST_TX_FAILURE;
    }

    const uint32_t flags = osThreadFlagsWait(
      RS422_EVENT_MASK,
      osFlagsWaitAny,
      timeout_ticks - elapsed_ticks);

    if (flags == osFlagsErrorTimeout)
    {
      g_rs422_tx_timeout_count++;
      return RS422_PING_TEST_TX_FAILURE;
    }

    if ((flags & osFlagsError) != 0u)
    {
      g_rs422_tx_error_count++;
      return RS422_PING_TEST_TX_FAILURE;
    }

    rs422_handle_tcp_context_reset_event(flags);
    rs422_handle_tx_done_event(flags);
  }

  return RS422_PING_TEST_PASS;
}

static int32_t rs422_ping_bringup_test(uint16_t sequence)
{
  HAL_StatusTypeDef tx_status;
  size_t tx_frame_length = 0u;
  uint32_t matching_pong_received = 0u;
  uint32_t wait_start_ticks;
  uint32_t pong_timeout_ticks;

  g_rs422_last_seq = sequence;

  if (g_rs422_tx_busy != 0u)
  {
    g_rs422_tx_busy_count++;
    return RS422_PING_TEST_TX_FAILURE;
  }

  g_rs422_ping_packet.version = PROTOCOL_VERSION;
  g_rs422_ping_packet.msg_id = MSG_PING;
  g_rs422_ping_packet.seq = sequence;
  g_rs422_ping_packet.length = 0u;

  if (protocol_encode(
        &g_rs422_ping_packet,
        g_rs422_tx_frame,
        sizeof(g_rs422_tx_frame),
        &tx_frame_length) != PROTO_OK)
  {
    return RS422_PING_TEST_ENCODE_FAILURE;
  }

  if ((osThreadFlagsClear(RS422_EVENT_TX_DONE) & osFlagsError) != 0u)
  {
    g_rs422_tx_error_count++;
    return RS422_PING_TEST_TX_FAILURE;
  }

  g_rs422_tx_busy = 1u;
  tx_status = HAL_UART_Transmit_IT(
    &huart4,
    g_rs422_tx_frame,
    (uint16_t)tx_frame_length);

  if (tx_status != HAL_OK)
  {
    g_rs422_tx_busy = 0u;

    if (tx_status == HAL_BUSY)
    {
      g_rs422_tx_busy_count++;
    }
    else
    {
      g_rs422_tx_error_count++;
    }

    return RS422_PING_TEST_TX_FAILURE;
  }

  if (rs422_wait_for_tx_complete(sequence, &matching_pong_received) !=
      RS422_PING_TEST_PASS)
  {
    return RS422_PING_TEST_TX_FAILURE;
  }

  if (matching_pong_received != 0u)
  {
    return RS422_PING_TEST_PASS;
  }

  pong_timeout_ticks =
    rs422_ms_to_kernel_ticks(RS422_BRINGUP_PONG_TIMEOUT_MS);
  wait_start_ticks = osKernelGetTickCount();

  while ((uint32_t)(osKernelGetTickCount() - wait_start_ticks) <
         pong_timeout_ticks)
  {
    if (rs422_process_rx_buffer(sequence, 1u) != 0u)
    {
      return RS422_PING_TEST_PASS;
    }

    const uint32_t elapsed_ticks =
      (uint32_t)(osKernelGetTickCount() - wait_start_ticks);

    if (elapsed_ticks >= pong_timeout_ticks)
    {
      break;
    }

    const uint32_t remaining_ticks = pong_timeout_ticks - elapsed_ticks;

    const uint32_t flags = osThreadFlagsWait(
      RS422_EVENT_MASK,
      osFlagsWaitAny,
      remaining_ticks);

    if (flags == osFlagsErrorTimeout)
    {
      break;
    }

    if ((flags & osFlagsError) != 0u)
    {
      return RS422_PING_TEST_RX_FAILURE;
    }

    rs422_handle_tcp_context_reset_event(flags);
    rs422_handle_tx_done_event(flags);
  }

  return RS422_PING_TEST_PONG_TIMEOUT;
}

static int32_t rs422_ping_bringup_run(void)
{
  int32_t last_failure = RS422_PING_TEST_PASS;

  g_rs422_ping_test_result = RS422_PING_TEST_NOT_RUN;
  g_rs422_last_msg_id = 0u;
  g_rs422_last_seq = 0u;
  g_rs422_rx_frame_count = 0u;
  g_rs422_test_total = 0u;
  g_rs422_test_success = 0u;
  g_rs422_test_fail = 0u;

  for (uint32_t test_index = 0u;
       test_index < RS422_BRINGUP_TEST_COUNT;
       test_index++)
  {
    const uint16_t sequence = (uint16_t)(test_index + 1u);
    const int32_t test_result = rs422_ping_bringup_test(sequence);

    g_rs422_test_total++;
    g_rs422_ping_test_result = test_result;

    if (test_result == RS422_PING_TEST_PASS)
    {
      g_rs422_test_success++;
    }
    else
    {
      g_rs422_test_fail++;
      last_failure = test_result;
    }

    if ((test_index + 1u) < RS422_BRINGUP_TEST_COUNT)
    {
      HAL_Delay(RS422_BRINGUP_INTER_TEST_DELAY_MS);
    }
  }

  if (g_rs422_test_fail == 0u)
  {
    return RS422_PING_TEST_PASS;
  }

  return last_failure;
}

static int32_t rs422_forward_packet(const protocol_packet_t *packet)
{
  size_t tx_frame_length = 0u;
  uint32_t matching_pong_received = 0u;

  if (packet == NULL)
  {
    g_rs422_tx_error_count++;
    return RS422_PING_TEST_ENCODE_FAILURE;
  }

  if (g_rs422_tx_busy != 0u)
  {
    g_rs422_tx_busy_count++;
    return RS422_PING_TEST_TX_FAILURE;
  }

  if ((protocol_encode(
         packet,
         g_rs422_tx_frame,
         sizeof(g_rs422_tx_frame),
         &tx_frame_length) != PROTO_OK) ||
      (tx_frame_length == 0u) ||
      (tx_frame_length > UINT16_MAX))
  {
    g_rs422_tx_error_count++;
    return RS422_PING_TEST_ENCODE_FAILURE;
  }

  if ((osThreadFlagsClear(RS422_EVENT_TX_DONE) & osFlagsError) != 0u)
  {
    g_rs422_tx_error_count++;
    return RS422_PING_TEST_TX_FAILURE;
  }

  if ((packet->msg_id == MSG_PING) &&
      (g_w5500_tcp_session_active != 0u))
  {
    g_rs422_tcp_ping_pending_seq = packet->seq;
    __DMB();
    g_rs422_tcp_ping_pending = 1u;
  }

  g_rs422_tx_busy = 1u;
  const HAL_StatusTypeDef tx_status = HAL_UART_Transmit_IT(
    &huart4,
    g_rs422_tx_frame,
    (uint16_t)tx_frame_length);

  if (tx_status != HAL_OK)
  {
    g_rs422_tx_busy = 0u;
    if (packet->msg_id == MSG_PING)
    {
      g_rs422_tcp_ping_pending = 0u;
      g_rs422_tcp_ping_pending_seq = 0u;
    }

    if (tx_status == HAL_BUSY)
    {
      g_rs422_tx_busy_count++;
    }
    else
    {
      g_rs422_tx_error_count++;
    }

    return RS422_PING_TEST_TX_FAILURE;
  }

  if ((packet->msg_id == MSG_PING) &&
      (g_diag_first_ping_seq_valid != 0u) &&
      (packet->seq == g_diag_first_ping_seq) &&
      (g_diag_rs422_ping_tx_ms == DIAG_TIMESTAMP_NOT_CAPTURED_MS))
  {
    const uint32_t now_ms = diagnostic_now_ms();
    g_diag_rs422_ping_tx_ms = now_ms;
    if (g_diag_first_ping_parsed_ms != DIAG_TIMESTAMP_NOT_CAPTURED_MS)
    {
      g_diag_ping_parsed_to_rs422_tx_ms =
        now_ms - g_diag_first_ping_parsed_ms;
    }
  }

  g_rs422_last_tx_msg_id = packet->msg_id;
  g_rs422_last_tx_seq = packet->seq;

  if (rs422_wait_for_tx_complete(
        packet->seq,
        &matching_pong_received) != RS422_PING_TEST_PASS)
  {
    if (packet->msg_id == MSG_PING)
    {
      g_rs422_tcp_ping_pending = 0u;
      g_rs422_tcp_ping_pending_seq = 0u;
    }
    return RS422_PING_TEST_TX_FAILURE;
  }

  return RS422_PING_TEST_PASS;
}

/* USER CODE END 0 */

int main(void)
{

  /* MCU Configuration--------------------------------------------------------*/

  /* Reset of all peripherals, Initializes the Flash interface and the Systick. */
  HAL_Init();

  /* Configure the system clock */
  SystemClock_Config();

  /* Initialize all configured peripherals */
  MX_GPIO_Init();
  MX_SPI2_Init();
  MX_UART4_Init();

  /* Init scheduler */
  osKernelInitialize();

  /* USER CODE BEGIN RTOS_QUEUES */
  g_gateway_queue_init_ok = 0u;
  rs422_cmd_queue = osMessageQueueNew(
    RS422_CMD_QUEUE_DEPTH,
    sizeof(protocol_packet_t),
    &rs422_cmd_queue_attributes);
  tcp_response_queue = osMessageQueueNew(
    TCP_RESPONSE_QUEUE_DEPTH,
    sizeof(protocol_packet_t),
    &tcp_response_queue_attributes);
  udp_telemetry_queue = osMessageQueueNew(
    UDP_TELEMETRY_QUEUE_DEPTH,
    sizeof(protocol_packet_t),
    &udp_telemetry_queue_attributes);

  if ((rs422_cmd_queue != NULL) &&
      (tcp_response_queue != NULL) &&
      (udp_telemetry_queue != NULL))
  {
    g_gateway_queue_init_ok = 1u;
  }
  /* USER CODE END RTOS_QUEUES */

  /* Create the thread(s) */
  /* creation of defaultTask */
  defaultTaskHandle = osThreadNew(StartDefaultTask, NULL, &defaultTask_attributes);

  /* creation of RS422Task */
  RS422TaskHandle = osThreadNew(StartRS422Task, NULL, &RS422Task_attributes);

  /* creation of EthernetTask */
  EthernetTaskHandle = osThreadNew(StartEthernetTask, NULL, &EthernetTask_attributes);

  /* creation of HealthTask */
  HealthTaskHandle = osThreadNew(StartHealthTask, NULL, &HealthTask_attributes);

  /* Start scheduler */
  osKernelStart();

  /* We should never get here as control is now taken by the scheduler */

  /* Infinite loop */
  while (1)
  {

  }
}

void SystemClock_Config(void)
{
  RCC_OscInitTypeDef RCC_OscInitStruct = {0};
  RCC_ClkInitTypeDef RCC_ClkInitStruct = {0};

  /** Configure the main internal regulator output voltage
  */
  HAL_PWREx_ControlVoltageScaling(PWR_REGULATOR_VOLTAGE_SCALE1_BOOST);

  /** Initializes the RCC Oscillators according to the specified parameters
  * in the RCC_OscInitTypeDef structure.
  */
  RCC_OscInitStruct.OscillatorType = RCC_OSCILLATORTYPE_HSI;
  RCC_OscInitStruct.HSIState = RCC_HSI_ON;
  RCC_OscInitStruct.HSICalibrationValue = RCC_HSICALIBRATION_DEFAULT;
  RCC_OscInitStruct.PLL.PLLState = RCC_PLL_ON;
  RCC_OscInitStruct.PLL.PLLSource = RCC_PLLSOURCE_HSI;
  RCC_OscInitStruct.PLL.PLLM = RCC_PLLM_DIV4;
  RCC_OscInitStruct.PLL.PLLN = 85;
  RCC_OscInitStruct.PLL.PLLP = RCC_PLLP_DIV2;
  RCC_OscInitStruct.PLL.PLLQ = RCC_PLLQ_DIV2;
  RCC_OscInitStruct.PLL.PLLR = RCC_PLLR_DIV2;
  if (HAL_RCC_OscConfig(&RCC_OscInitStruct) != HAL_OK)
  {
    Error_Handler();
  }

  /** Initializes the CPU, AHB and APB buses clocks
  */
  RCC_ClkInitStruct.ClockType = RCC_CLOCKTYPE_HCLK|RCC_CLOCKTYPE_SYSCLK
                              |RCC_CLOCKTYPE_PCLK1|RCC_CLOCKTYPE_PCLK2;
  RCC_ClkInitStruct.SYSCLKSource = RCC_SYSCLKSOURCE_PLLCLK;
  RCC_ClkInitStruct.AHBCLKDivider = RCC_SYSCLK_DIV1;
  RCC_ClkInitStruct.APB1CLKDivider = RCC_HCLK_DIV1;
  RCC_ClkInitStruct.APB2CLKDivider = RCC_HCLK_DIV1;

  if (HAL_RCC_ClockConfig(&RCC_ClkInitStruct, FLASH_LATENCY_4) != HAL_OK)
  {
    Error_Handler();
  }
}

static void MX_SPI2_Init(void)
{

  /* SPI2 parameter configuration*/
  hspi2.Instance = SPI2;
  hspi2.Init.Mode = SPI_MODE_MASTER;
  hspi2.Init.Direction = SPI_DIRECTION_2LINES;
  hspi2.Init.DataSize = SPI_DATASIZE_8BIT;
  hspi2.Init.CLKPolarity = SPI_POLARITY_LOW;
  hspi2.Init.CLKPhase = SPI_PHASE_1EDGE;
  hspi2.Init.NSS = SPI_NSS_SOFT;
  hspi2.Init.BaudRatePrescaler = SPI_BAUDRATEPRESCALER_16;
  hspi2.Init.FirstBit = SPI_FIRSTBIT_MSB;
  hspi2.Init.TIMode = SPI_TIMODE_DISABLE;
  hspi2.Init.CRCCalculation = SPI_CRCCALCULATION_DISABLE;
  hspi2.Init.CRCPolynomial = 7;
  hspi2.Init.CRCLength = SPI_CRC_LENGTH_DATASIZE;
  hspi2.Init.NSSPMode = SPI_NSS_PULSE_ENABLE;
  if (HAL_SPI_Init(&hspi2) != HAL_OK)
  {
    Error_Handler();
  }

}

static void MX_UART4_Init(void)
{

  huart4.Instance = UART4;
  huart4.Init.BaudRate = 115200;
  huart4.Init.WordLength = UART_WORDLENGTH_8B;
  huart4.Init.StopBits = UART_STOPBITS_1;
  huart4.Init.Parity = UART_PARITY_NONE;
  huart4.Init.Mode = UART_MODE_TX_RX;
  huart4.Init.HwFlowCtl = UART_HWCONTROL_NONE;
  huart4.Init.OverSampling = UART_OVERSAMPLING_16;
  huart4.Init.OneBitSampling = UART_ONE_BIT_SAMPLE_DISABLE;
  huart4.Init.ClockPrescaler = UART_PRESCALER_DIV1;
  huart4.AdvancedInit.AdvFeatureInit = UART_ADVFEATURE_NO_INIT;
  if (HAL_UART_Init(&huart4) != HAL_OK)
  {
    Error_Handler();
  }
  if (HAL_UARTEx_SetTxFifoThreshold(&huart4, UART_TXFIFO_THRESHOLD_1_8) != HAL_OK)
  {
    Error_Handler();
  }
  if (HAL_UARTEx_SetRxFifoThreshold(&huart4, UART_RXFIFO_THRESHOLD_1_8) != HAL_OK)
  {
    Error_Handler();
  }
  if (HAL_UARTEx_DisableFifoMode(&huart4) != HAL_OK)
  {
    Error_Handler();
  }

}

static void MX_GPIO_Init(void)
{
  GPIO_InitTypeDef GPIO_InitStruct = {0};

  /* GPIO Ports Clock Enable */
  __HAL_RCC_GPIOC_CLK_ENABLE();
  __HAL_RCC_GPIOF_CLK_ENABLE();
  __HAL_RCC_GPIOA_CLK_ENABLE();
  __HAL_RCC_GPIOB_CLK_ENABLE();

  /*Configure GPIO pin Output Level */
  HAL_GPIO_WritePin(LD2_GPIO_Port, LD2_Pin, GPIO_PIN_RESET);

  /*Configure GPIO pin Output Level */
  HAL_GPIO_WritePin(GPIOB, W5500_CS_Pin|W5500_RST_Pin, GPIO_PIN_SET);

  /*Configure GPIO pin : B1_Pin */
  GPIO_InitStruct.Pin = B1_Pin;
  GPIO_InitStruct.Mode = GPIO_MODE_IT_RISING;
  GPIO_InitStruct.Pull = GPIO_NOPULL;
  HAL_GPIO_Init(B1_GPIO_Port, &GPIO_InitStruct);

  /*Configure GPIO pins : LPUART1_TX_Pin LPUART1_RX_Pin */
  GPIO_InitStruct.Pin = LPUART1_TX_Pin|LPUART1_RX_Pin;
  GPIO_InitStruct.Mode = GPIO_MODE_AF_PP;
  GPIO_InitStruct.Pull = GPIO_NOPULL;
  GPIO_InitStruct.Speed = GPIO_SPEED_FREQ_LOW;
  GPIO_InitStruct.Alternate = GPIO_AF12_LPUART1;
  HAL_GPIO_Init(GPIOA, &GPIO_InitStruct);

  /*Configure GPIO pin : LD2_Pin */
  GPIO_InitStruct.Pin = LD2_Pin;
  GPIO_InitStruct.Mode = GPIO_MODE_OUTPUT_PP;
  GPIO_InitStruct.Pull = GPIO_NOPULL;
  GPIO_InitStruct.Speed = GPIO_SPEED_FREQ_LOW;
  HAL_GPIO_Init(LD2_GPIO_Port, &GPIO_InitStruct);

  /*Configure GPIO pin : W5500_CS_Pin */
  GPIO_InitStruct.Pin = W5500_CS_Pin;
  GPIO_InitStruct.Mode = GPIO_MODE_OUTPUT_PP;
  GPIO_InitStruct.Pull = GPIO_NOPULL;
  GPIO_InitStruct.Speed = GPIO_SPEED_FREQ_HIGH;
  HAL_GPIO_Init(W5500_CS_GPIO_Port, &GPIO_InitStruct);

  /*Configure GPIO pin : W5500_RST_Pin */
  GPIO_InitStruct.Pin = W5500_RST_Pin;
  GPIO_InitStruct.Mode = GPIO_MODE_OUTPUT_PP;
  GPIO_InitStruct.Pull = GPIO_NOPULL;
  GPIO_InitStruct.Speed = GPIO_SPEED_FREQ_LOW;
  HAL_GPIO_Init(W5500_RST_GPIO_Port, &GPIO_InitStruct);

  /*Configure GPIO pin : W5500_INT_Pin */
  GPIO_InitStruct.Pin = W5500_INT_Pin;
  GPIO_InitStruct.Mode = GPIO_MODE_IT_FALLING;
  GPIO_InitStruct.Pull = GPIO_NOPULL;
  HAL_GPIO_Init(W5500_INT_GPIO_Port, &GPIO_InitStruct);

  /* EXTI interrupt init*/
  HAL_NVIC_SetPriority(EXTI9_5_IRQn, 5, 0);
  HAL_NVIC_EnableIRQ(EXTI9_5_IRQn);

  HAL_NVIC_SetPriority(EXTI15_10_IRQn, 5, 0);
  HAL_NVIC_EnableIRQ(EXTI15_10_IRQn);

}

/* USER CODE BEGIN 4 */
void HAL_UART_TxCpltCallback(UART_HandleTypeDef *huart)
{
  if ((huart != NULL) &&
      (huart->Instance == UART4) &&
      (RS422TaskHandle != NULL))
  {
    (void)osThreadFlagsSet(RS422TaskHandle, RS422_EVENT_TX_DONE);
  }
}

void HAL_UART_RxCpltCallback(UART_HandleTypeDef *huart)
{
  if ((huart != NULL) && (huart->Instance == UART4))
  {
    rs422_rx_ring_push_from_isr(g_uart4_rx_byte);

    if (HAL_UART_Receive_IT(&huart4, &g_uart4_rx_byte, 1u) != HAL_OK)
    {
      g_rs422_uart_rx_error_count++;
    }

    if (RS422TaskHandle != NULL)
    {
      (void)osThreadFlagsSet(RS422TaskHandle, RS422_EVENT_RX);
    }
  }
}

void HAL_UART_ErrorCallback(UART_HandleTypeDef *huart)
{
  if ((huart != NULL) && (huart->Instance == UART4))
  {
    g_rs422_uart_rx_error_count++;

    if ((huart->RxState == HAL_UART_STATE_READY) &&
        (HAL_UART_Receive_IT(&huart4, &g_uart4_rx_byte, 1u) != HAL_OK))
    {
      g_rs422_uart_rx_error_count++;
    }

    if (RS422TaskHandle != NULL)
    {
      (void)osThreadFlagsSet(RS422TaskHandle, RS422_EVENT_RX);
    }
  }
}

/* USER CODE END 4 */

void StartDefaultTask(void *argument)
{
  for(;;)
  {
    osDelay(1);
  }
}

void StartRS422Task(void *argument)
{
  /* USER CODE BEGIN StartRS422Task */
  g_rs422_rx_head = 0u;
  g_rs422_rx_tail = 0u;
  g_rs422_rx_overflow_count = 0u;
  g_rs422_uart_rx_error_count = 0u;
  g_rs422_tx_busy = 0u;
  g_rs422_tx_complete_count = 0u;
  g_rs422_tx_busy_count = 0u;
  g_rs422_tx_error_count = 0u;
  g_rs422_tx_timeout_count = 0u;
  g_rs422_cmd_dequeue_count = 0u;
  g_rs422_forwarded_pong_rx_count = 0u;
  g_tcp_response_enqueue_success_count = 0u;
  g_tcp_response_enqueue_fail_count = 0u;
  g_rs422_telemetry_rx_count = 0u;
  g_udp_telemetry_enqueue_success_count = 0u;
  g_udp_telemetry_enqueue_fail_count = 0u;
  g_rs422_telemetry_forwarding_enabled = 0u;
  g_rs422_tcp_ping_pending = 0u;
  g_rs422_tcp_ping_pending_seq = 0u;
  g_rs422_last_tx_msg_id = 0u;
  g_rs422_last_tx_seq = 0u;
  g_rs422_last_valid_frame_tick = 0u;
  g_rs422_has_valid_frame = 0u;
  g_rs422_diag_last_valid_frame_ms = DIAG_TIMESTAMP_NOT_CAPTURED_MS;
  g_rs422_diag_timeout_transition_ms = DIAG_TIMESTAMP_NOT_CAPTURED_MS;
  g_rs422_diag_recovery_first_valid_ms = DIAG_TIMESTAMP_NOT_CAPTURED_MS;
  g_rs422_diag_recovery_comm_ok_ms = DIAG_TIMESTAMP_NOT_CAPTURED_MS;
  g_rs422_diag_fault_detection_ms = DIAG_TIMESTAMP_NOT_CAPTURED_MS;
  g_rs422_diag_recovery_ms = DIAG_TIMESTAMP_NOT_CAPTURED_MS;
  g_rs422_diag_timeout_transition_tick = UINT32_MAX;
  g_rs422_diag_recovery_first_valid_tick = UINT32_MAX;
  g_rs422_diag_recovery_comm_ok_tick = UINT32_MAX;
  stream_parser_init(&g_rs422_parser);

  if (HAL_UART_Receive_IT(&huart4, &g_uart4_rx_byte, 1u) == HAL_OK)
  {
    g_rs422_ping_test_result = rs422_ping_bringup_run();
  }
  else
  {
    g_rs422_uart_rx_error_count++;
    g_rs422_ping_test_result = RS422_PING_TEST_RX_FAILURE;
  }

  g_rs422_telemetry_forwarding_enabled = 1u;

  /* Infinite loop */
  for(;;)
  {
    (void)rs422_process_rx_buffer(0u, 0u);

    while ((rs422_cmd_queue != NULL) &&
           (osMessageQueueGet(
              rs422_cmd_queue,
              &g_rs422_command_packet,
              NULL,
              0u) == osOK))
    {
      g_rs422_cmd_dequeue_count++;
      (void)rs422_forward_packet(&g_rs422_command_packet);
      (void)rs422_process_rx_buffer(0u, 0u);
    }

    const uint32_t flags = osThreadFlagsWait(
      RS422_EVENT_MASK,
      osFlagsWaitAny,
      osWaitForever);

    if ((flags & osFlagsError) == 0u)
    {
      rs422_handle_tcp_context_reset_event(flags);
      rs422_handle_tx_done_event(flags);
    }
    else
    {
      g_rs422_tx_error_count++;
    }
  }
  /* USER CODE END StartRS422Task */
}

void StartEthernetTask(void *argument)
{
  /* USER CODE BEGIN StartEthernetTask */
  uint8_t version = 0u;
  /* Boot/startup and normal socket lifecycle retries are not link recovery. */
  uint32_t tcp_lifecycle_restart_pending = 0u;

  g_w5500_net_config_ok = 0u;
  g_w5500_net_readback_ok = 0u;
  g_w5500_net_write_status = -1;
  g_w5500_net_read_status = -1;
  g_w5500_tcp_init_ok = 0u;
  g_w5500_tcp_listen_ok = 0u;
  g_w5500_socket0_status = W5500_SOCKET0_STATUS_CLOSED;
  g_w5500_socket0_spi_status = -1;
  g_w5500_tcp_rx_bytes = 0u;
  g_w5500_tcp_tx_bytes = 0u;
  g_w5500_tcp_valid_frame_count = 0u;
  g_w5500_tcp_ping_count = 0u;
  g_w5500_tcp_pong_count = 0u;
  g_w5500_tcp_last_rx_msg_id = 0u;
  g_w5500_tcp_last_rx_seq = 0u;
  g_w5500_tcp_last_tx_msg_id = 0u;
  g_w5500_tcp_last_tx_seq = 0u;
  g_w5500_tcp_rx_error_count = 0u;
  g_w5500_tcp_tx_error_count = 0u;
  g_w5500_tcp_last_rx_status = -1;
  g_w5500_tcp_last_tx_status = -1;
  g_w5500_phycfgr = 0u;
  g_w5500_link_up = 0u;
  g_w5500_link_down_count = 0u;
  g_w5500_link_recovery_count = 0u;
  g_w5500_tcp_recovery_pending = 0u;
  g_w5500_tcp_recovery_attempt_count = 0u;
  g_w5500_tcp_recovery_success_count = 0u;
  g_w5500_tcp_recovery_fail_count = 0u;
  ethernet_diag_initialize();
  g_w5500_tcp_session_active = 0u;
  g_w5500_tcp_stale_response_drop_count = 0u;
  g_w5500_data_service_cycle_count = 0u;
  g_w5500_data_deadline_miss_count = 0u;
  g_w5500_data_overrun_count = 0u;
  g_w5500_data_max_start_late_ticks = 0u;
  g_w5500_data_max_exec_cycles = 0u;
  g_w5500_data_max_exec_us = 0u;
  g_w5500_data_cycle_counter_available = 0u;
  g_w5500_data_system_core_clock_hz = 0u;
  g_w5500_data_kernel_tick_hz = 0u;
  g_w5500_data_period_cycles = 0u;
  g_w5500_data_timing_reference_valid = 0u;
  g_rs422_cmd_enqueue_success_count = 0u;
  g_rs422_cmd_enqueue_fail_count = 0u;
  g_tcp_response_dequeue_count = 0u;
  g_w5500_udp_open_ok = 0u;
  g_w5500_udp_socket1_status = W5500_SOCKET1_STATUS_CLOSED;
  g_w5500_udp_socket1_spi_status = -1;
  g_w5500_udp_tx_packet_count = 0u;
  g_w5500_udp_tx_bytes = 0u;
  g_w5500_udp_tx_error_count = 0u;
  g_w5500_udp_last_tx_seq = 0u;
  g_w5500_udp_last_tx_status = -1;
  g_w5500_udp_next_seq = 1u;
  g_udp_telemetry_dequeue_count = 0u;
  stream_parser_init(&g_tcp_parser);
  for (uint16_t index = 0u; index < W5500_GAR_LENGTH; index++)
  {
    g_w5500_gar_readback[index] = 0u;
    g_w5500_subr_readback[index] = 0u;
    g_w5500_sipr_readback[index] = 0u;
  }
  for (uint16_t index = 0u; index < W5500_SHAR_LENGTH; index++)
  {
    g_w5500_shar_readback[index] = 0u;
  }

  CoreDebug->DEMCR |= CoreDebug_DEMCR_TRCENA_Msk;
  DWT->CYCCNT = 0u;
  DWT->CTRL |= DWT_CTRL_CYCCNTENA_Msk;
  if ((DWT->CTRL & DWT_CTRL_CYCCNTENA_Msk) != 0u)
  {
    g_w5500_data_cycle_counter_available = 1u;
  }

  w5500_hardware_reset();
  const HAL_StatusTypeDef status = w5500_read_version(&version);
  g_w5500_version = version;
  g_w5500_spi_status = (int32_t)status;

  if ((status == HAL_OK) && (version == 0x04u))
  {
    const HAL_StatusTypeDef write_status = w5500_write_network_config();
    g_w5500_net_write_status = (int32_t)write_status;

    if (write_status == HAL_OK)
    {
      g_w5500_net_config_ok = 1u;
      const HAL_StatusTypeDef read_status = w5500_read_network_config();
      g_w5500_net_read_status = (int32_t)read_status;

      if ((read_status == HAL_OK) &&
          (w5500_network_readback_matches() != 0u))
      {
        g_w5500_net_readback_ok = 1u;
      }
    }
  }

  if ((g_w5500_net_config_ok != 0u) &&
      (g_w5500_net_readback_ok != 0u))
  {
    if (w5500_start_tcp_server() != HAL_OK)
    {
      tcp_lifecycle_restart_pending = 1u;
    }
  }

  if ((g_w5500_net_config_ok != 0u) &&
      (g_w5500_net_readback_ok != 0u))
  {
    const HAL_StatusTypeDef udp_open_status = w5500_start_udp_socket();
    g_w5500_udp_socket1_spi_status = (int32_t)udp_open_status;
    if (udp_open_status == HAL_OK)
    {
      g_w5500_udp_open_ok = 1u;
    }
  }

  const uint32_t phy_period_ticks =
    rs422_ms_to_kernel_ticks(W5500_PHY_POLL_PERIOD_MS);
  const uint32_t data_service_period_ticks =
    rs422_ms_to_kernel_ticks(W5500_DATA_SERVICE_PERIOD_MS);
  const uint32_t kernel_tick_hz = osKernelGetTickFreq();
  const uint32_t system_core_clock_hz = SystemCoreClock;
  const uint32_t data_service_period_cycles = (kernel_tick_hz != 0u) ?
    (uint32_t)((((uint64_t)system_core_clock_hz *
                 data_service_period_ticks) +
                (kernel_tick_hz - 1u)) /
               kernel_tick_hz) : 0u;
  const uint32_t tcp_transient_timeout_ticks =
    rs422_ms_to_kernel_ticks(W5500_TCP_TRANSIENT_TIMEOUT_MS);
  const uint32_t tcp_recovery_retry_ticks =
    rs422_ms_to_kernel_ticks(W5500_TCP_RECOVERY_RETRY_MS);

  g_w5500_data_system_core_clock_hz = system_core_clock_hz;
  g_w5500_data_kernel_tick_hz = kernel_tick_hz;
  g_w5500_data_period_cycles = data_service_period_cycles;
  if ((system_core_clock_hz != 0u) &&
      (kernel_tick_hz != 0u) &&
      (data_service_period_cycles != 0u))
  {
    g_w5500_data_timing_reference_valid = 1u;
  }

  uint32_t next_phy_tick = osKernelGetTickCount();
  uint32_t next_data_service_tick = next_phy_tick;
  uint32_t next_tcp_restart_tick = next_phy_tick;
  uint32_t socket_state_enter_tick = next_phy_tick;
  uint32_t phy_link_state_initialized = 0u;
  uint32_t phy_link_was_established = 0u;
  uint32_t previous_link_up = 0u;
  uint32_t socket_state_initialized = 0u;
  uint32_t graceful_disconnect_pending = 0u;
  uint32_t pending_ethernet_events = 0u;
  uint8_t previous_socket_status = W5500_SOCKET0_STATUS_CLOSED;

  /* Infinite loop */
  for(;;)
  {
    const uint32_t current_tick = osKernelGetTickCount();
    uint32_t data_cycle_start_cycles = 0u;
    const uint32_t control_service_due =
      ((int32_t)(current_tick - next_phy_tick) >= 0) ? 1u : 0u;
    const uint32_t data_service_due =
      ((int32_t)(current_tick - next_data_service_tick) >= 0) ? 1u : 0u;
    const uint32_t tcp_response_event = pending_ethernet_events &
      ETHERNET_EVENT_TCP_RESPONSE_READY;
    pending_ethernet_events = 0u;

    if (control_service_due != 0u)
    {
      uint8_t phycfgr = 0u;
      const HAL_StatusTypeDef phy_status = w5500_read_common_register(
        W5500_PHYCFGR_ADDRESS, &phycfgr);

      if (phy_status == HAL_OK)
      {
        const uint32_t current_link_up =
          ((phycfgr & W5500_PHYCFGR_LNK) != 0u) ? 1u : 0u;

        g_w5500_phycfgr = phycfgr;
        g_w5500_link_up = current_link_up;

        if (phy_link_state_initialized == 0u)
        {
          phy_link_state_initialized = 1u;
          previous_link_up = current_link_up;

          if (current_link_up != 0u)
          {
            phy_link_was_established = 1u;
          }
        }
        else if (current_link_up != previous_link_up)
        {
          if (current_link_up == 0u)
          {
            if (phy_link_was_established != 0u)
            {
              g_w5500_link_down_count++;
              ethernet_diag_arm_recovery(osKernelGetTickCount());
              g_w5500_tcp_recovery_pending = 1u;
              g_w5500_tcp_init_ok = 0u;
              g_w5500_tcp_listen_ok = 0u;
              tcp_lifecycle_restart_pending = 0u;
              graceful_disconnect_pending = 0u;
              socket_state_initialized = 0u;
              w5500_tcp_invalidate_connection_context();
            }
          }
          else
          {
            if (phy_link_was_established == 0u)
            {
              phy_link_was_established = 1u;
              next_tcp_restart_tick = osKernelGetTickCount();
            }
            else if (g_w5500_tcp_recovery_pending != 0u)
            {
              g_w5500_link_recovery_count++;
              ethernet_diag_record_link_up(osKernelGetTickCount());
              next_tcp_restart_tick = osKernelGetTickCount();
            }
          }

          previous_link_up = current_link_up;
        }
      }
      g_w5500_phy_spi_status = (int32_t)phy_status;

      if ((g_w5500_net_config_ok != 0u) &&
          (g_w5500_net_readback_ok != 0u) &&
          (g_w5500_socket0_spi_status == (int32_t)HAL_OK))
      {
        const uint8_t socket_status = g_w5500_socket0_status;
        const uint32_t socket_tick = osKernelGetTickCount();

        if (g_w5500_link_up != 0u)
        {
          if (g_w5500_tcp_recovery_pending != 0u)
          {
            if ((int32_t)(socket_tick - next_tcp_restart_tick) >= 0)
            {
              g_w5500_tcp_recovery_attempt_count++;
              const HAL_StatusTypeDef recovery_status =
                w5500_restart_tcp_server();

              if (recovery_status == HAL_OK)
              {
                g_w5500_tcp_recovery_pending = 0u;
                g_w5500_tcp_recovery_success_count++;
                tcp_lifecycle_restart_pending = 0u;
                graceful_disconnect_pending = 0u;
                socket_state_initialized = 1u;
                previous_socket_status = W5500_SOCKET0_STATUS_LISTEN;
                socket_state_enter_tick = osKernelGetTickCount();
              }
              else
              {
                g_w5500_tcp_recovery_fail_count++;
                next_tcp_restart_tick =
                  osKernelGetTickCount() + tcp_recovery_retry_ticks;
                socket_state_initialized = 0u;
              }
            }
          }
          else if (tcp_lifecycle_restart_pending != 0u)
          {
            if ((int32_t)(socket_tick - next_tcp_restart_tick) >= 0)
            {
              const HAL_StatusTypeDef restart_status =
                w5500_restart_tcp_server();

              if (restart_status == HAL_OK)
              {
                tcp_lifecycle_restart_pending = 0u;
                graceful_disconnect_pending = 0u;
                socket_state_initialized = 1u;
                previous_socket_status = W5500_SOCKET0_STATUS_LISTEN;
                socket_state_enter_tick = osKernelGetTickCount();
              }
              else
              {
                next_tcp_restart_tick =
                  osKernelGetTickCount() + tcp_recovery_retry_ticks;
                socket_state_initialized = 0u;
              }
            }
          }
          else
          {
            switch (socket_status)
            {
              case W5500_SOCKET0_STATUS_ESTABLISHED:
                graceful_disconnect_pending = 0u;
                break;

              case W5500_SOCKET0_STATUS_CLOSE_WAIT:
                if (graceful_disconnect_pending == 0u)
                {
                  g_w5500_tcp_init_ok = 0u;
                  g_w5500_tcp_listen_ok = 0u;
                  const HAL_StatusTypeDef disconnect_status =
                    w5500_socket0_execute_command(
                      W5500_SOCKET0_DISCON_COMMAND);
                  g_w5500_socket0_spi_status =
                    (int32_t)disconnect_status;

                  if (disconnect_status == HAL_OK)
                  {
                    graceful_disconnect_pending = 1u;
                    socket_state_enter_tick = osKernelGetTickCount();
                  }
                  else
                  {
                    tcp_lifecycle_restart_pending = 1u;
                    next_tcp_restart_tick =
                      osKernelGetTickCount() + tcp_recovery_retry_ticks;
                  }
                }
                else if ((uint32_t)(
                           socket_tick - socket_state_enter_tick) >=
                         tcp_transient_timeout_ticks)
                {
                  tcp_lifecycle_restart_pending = 1u;
                  next_tcp_restart_tick = socket_tick;
                  graceful_disconnect_pending = 0u;
                }
                break;

              case W5500_SOCKET0_STATUS_CLOSED:
                if (w5500_start_tcp_server() == HAL_OK)
                {
                  graceful_disconnect_pending = 0u;
                  socket_state_initialized = 1u;
                  previous_socket_status = W5500_SOCKET0_STATUS_LISTEN;
                  socket_state_enter_tick = osKernelGetTickCount();
                  w5500_tcp_discard_stale_responses();
                }
                else
                {
                  tcp_lifecycle_restart_pending = 1u;
                  next_tcp_restart_tick =
                    osKernelGetTickCount() + tcp_recovery_retry_ticks;
                  socket_state_initialized = 0u;
                }
                break;

              case W5500_SOCKET0_STATUS_INIT:
                g_w5500_tcp_listen_ok = 0u;
                if (w5500_listen_tcp_server() == HAL_OK)
                {
                  g_w5500_tcp_init_ok = 1u;
                  graceful_disconnect_pending = 0u;
                  socket_state_initialized = 1u;
                  previous_socket_status = W5500_SOCKET0_STATUS_LISTEN;
                  socket_state_enter_tick = osKernelGetTickCount();
                  w5500_tcp_discard_stale_responses();
                }
                else
                {
                  tcp_lifecycle_restart_pending = 1u;
                  next_tcp_restart_tick =
                    osKernelGetTickCount() + tcp_recovery_retry_ticks;
                  socket_state_initialized = 0u;
                }
                break;

              case W5500_SOCKET0_STATUS_LISTEN:
                g_w5500_tcp_init_ok = 1u;
                g_w5500_tcp_listen_ok = 1u;
                graceful_disconnect_pending = 0u;
                break;

              default:
                if (w5500_tcp_is_transient_state(socket_status) == 0u)
                {
                  g_w5500_tcp_init_ok = 0u;
                  g_w5500_tcp_listen_ok = 0u;
                  tcp_lifecycle_restart_pending = 1u;
                  next_tcp_restart_tick = socket_tick;
                  graceful_disconnect_pending = 0u;
                }
                else if ((uint32_t)(
                           socket_tick - socket_state_enter_tick) >=
                         tcp_transient_timeout_ticks)
                {
                  g_w5500_tcp_init_ok = 0u;
                  g_w5500_tcp_listen_ok = 0u;
                  tcp_lifecycle_restart_pending = 1u;
                  next_tcp_restart_tick = socket_tick;
                  graceful_disconnect_pending = 0u;
                }
                break;
            }
          }
        }
      }

      const uint32_t deadline_now = osKernelGetTickCount();
      do
      {
        next_phy_tick += phy_period_ticks;
      }
      while ((int32_t)(deadline_now - next_phy_tick) >= 0);
    }

    if (data_service_due != 0u)
    {
      const int32_t start_late_ticks =
        (int32_t)(osKernelGetTickCount() - next_data_service_tick);
      g_w5500_data_service_cycle_count++;

      if (start_late_ticks > 0)
      {
        g_w5500_data_deadline_miss_count++;
        if ((uint32_t)start_late_ticks >
            g_w5500_data_max_start_late_ticks)
        {
          g_w5500_data_max_start_late_ticks =
            (uint32_t)start_late_ticks;
        }
      }

      if (g_w5500_data_cycle_counter_available != 0u)
      {
        data_cycle_start_cycles = DWT->CYCCNT;
      }
    }

    if ((data_service_due != 0u) &&
        (g_w5500_net_config_ok != 0u) &&
        (g_w5500_net_readback_ok != 0u) &&
        (g_w5500_link_up != 0u))
    {
      uint8_t socket_status = W5500_SOCKET0_STATUS_CLOSED;
      const HAL_StatusTypeDef socket_spi_status =
        w5500_socket0_read_register(
          W5500_SOCKET0_SR_ADDRESS, &socket_status);
      g_w5500_socket0_spi_status = (int32_t)socket_spi_status;

      if (socket_spi_status == HAL_OK)
      {
        const uint32_t socket_tick = osKernelGetTickCount();
        g_w5500_socket0_status = socket_status;

        if ((socket_state_initialized == 0u) ||
            (socket_status != previous_socket_status))
        {
          socket_state_initialized = 1u;
          previous_socket_status = socket_status;
          socket_state_enter_tick = socket_tick;
        }

        if (socket_status == W5500_SOCKET0_STATUS_ESTABLISHED)
        {
          graceful_disconnect_pending = 0u;
          if (g_w5500_tcp_session_active == 0u)
          {
            diagnostic_begin_tcp_session(socket_tick);
            stream_parser_init(&g_tcp_parser);
            w5500_tcp_discard_stale_responses();
            __DMB();
            g_w5500_tcp_session_active = 1u;
          }
        }
        else if (g_w5500_tcp_session_active != 0u)
        {
          g_w5500_tcp_init_ok = 0u;
          g_w5500_tcp_listen_ok = 0u;
          w5500_tcp_invalidate_connection_context();
        }
      }
    }

    if (((data_service_due != 0u) || (tcp_response_event != 0u)) &&
        (g_w5500_link_up != 0u) &&
        (g_w5500_tcp_session_active != 0u) &&
        (g_w5500_socket0_status == W5500_SOCKET0_STATUS_ESTABLISHED))
    {
      if (data_service_due != 0u)
      {
        const HAL_StatusTypeDef rx_status = w5500_tcp_process_rx();
        g_w5500_tcp_last_rx_status = (int32_t)rx_status;
        if (rx_status != HAL_OK)
        {
          g_w5500_tcp_rx_error_count++;
        }
      }

      w5500_tcp_drain_response_queue();
    }

    if ((data_service_due != 0u) && (g_w5500_udp_open_ok != 0u))
    {
      uint8_t udp_socket_status = W5500_SOCKET1_STATUS_CLOSED;
      const HAL_StatusTypeDef udp_socket_spi_status =
        w5500_socket1_read_register(
          W5500_SOCKET1_SR_ADDRESS, &udp_socket_status);
      g_w5500_udp_socket1_spi_status = (int32_t)udp_socket_spi_status;

      if (udp_socket_spi_status == HAL_OK)
      {
        g_w5500_udp_socket1_status = udp_socket_status;
        if ((udp_socket_status == W5500_SOCKET1_STATUS_UDP) &&
            (g_w5500_link_up != 0u))
        {
          if (W5500_UDP_LOCAL_TELEMETRY_ENABLED != 0u)
          {
            w5500_udp_send_telemetry();
          }

          for (uint32_t drain_index = 0u;
               drain_index < UDP_TELEMETRY_DRAIN_LIMIT;
               drain_index++)
          {
            if ((udp_telemetry_queue == NULL) ||
                (osMessageQueueGet(
                   udp_telemetry_queue,
                   &g_udp_forward_packet,
                   NULL,
                   0u) != osOK))
            {
              break;
            }

            g_udp_telemetry_dequeue_count++;
            if (w5500_udp_forward_packet(&g_udp_forward_packet) != HAL_OK)
            {
              break;
            }
          }
        }
      }
    }

    if ((data_service_due != 0u) &&
        (g_w5500_data_cycle_counter_available != 0u))
    {
      const uint32_t elapsed_cycles =
        DWT->CYCCNT - data_cycle_start_cycles;

      if ((g_w5500_data_timing_reference_valid != 0u) &&
          (elapsed_cycles >= g_w5500_data_period_cycles))
      {
        g_w5500_data_overrun_count++;
      }

      if (elapsed_cycles > g_w5500_data_max_exec_cycles)
      {
        uint32_t elapsed_us = 0u;
        if (g_w5500_data_timing_reference_valid != 0u)
        {
          const uint64_t elapsed_us_numerator =
            ((uint64_t)elapsed_cycles * 1000000ULL) +
            (g_w5500_data_system_core_clock_hz - 1u);
          elapsed_us = (uint32_t)(
            elapsed_us_numerator / g_w5500_data_system_core_clock_hz);
        }

        /* Publish the derived value before its corresponding cycle maximum. */
        g_w5500_data_max_exec_us = elapsed_us;
        __DMB();
        g_w5500_data_max_exec_cycles = elapsed_cycles;
      }
    }

    if (data_service_due != 0u)
    {
      const uint32_t deadline_now = osKernelGetTickCount();
      do
      {
        next_data_service_tick += data_service_period_ticks;
      }
      while ((int32_t)(deadline_now - next_data_service_tick) >= 0);
    }

    const uint32_t wait_start_tick = osKernelGetTickCount();
    const int32_t data_wait =
      (int32_t)(next_data_service_tick - wait_start_tick);
    const int32_t phy_wait = (int32_t)(next_phy_tick - wait_start_tick);
    uint32_t wait_ticks = 0u;

    if ((data_wait > 0) && (phy_wait > 0))
    {
      wait_ticks = ((uint32_t)data_wait < (uint32_t)phy_wait) ?
        (uint32_t)data_wait : (uint32_t)phy_wait;
    }

    const uint32_t wait_flags = osThreadFlagsWait(
      ETHERNET_EVENT_MASK,
      osFlagsWaitAny,
      wait_ticks);

    if ((wait_flags & osFlagsError) == 0u)
    {
      pending_ethernet_events = wait_flags;
    }
    else if ((wait_flags == osFlagsErrorTimeout) ||
             (wait_flags == osFlagsErrorResource))
    {
      /* A periodic deadline without an event is a normal wake condition. */
    }
  }
  /* USER CODE END StartEthernetTask */
}

void StartHealthTask(void *argument)
{
  /* USER CODE BEGIN StartHealthTask */
  const uint32_t health_period_ticks =
    rs422_ms_to_kernel_ticks(HEALTH_TASK_PERIOD_MS);
  const uint32_t comm_timeout_ticks =
    rs422_ms_to_kernel_ticks(RS422_COMM_TIMEOUT_MS);
  const uint32_t health_start_tick = osKernelGetTickCount();
  uint32_t next_wake_tick = health_start_tick;

  g_rs422_comm_state = COMM_INIT;
  g_rs422_comm_timeout_count = 0u;
  g_rs422_comm_recovery_count = 0u;

  /* Infinite loop */
  for(;;)
  {
    next_wake_tick += health_period_ticks;
    (void)osDelayUntil(next_wake_tick);

    const uint32_t current_tick = osKernelGetTickCount();
    const uint32_t has_valid_frame = g_rs422_has_valid_frame;
    const uint32_t last_valid_frame_tick =
      g_rs422_last_valid_frame_tick;

    if (has_valid_frame != 0u)
    {
      if ((uint32_t)(current_tick - last_valid_frame_tick) >=
          comm_timeout_ticks)
      {
        if (g_rs422_comm_state != COMM_TIMEOUT)
        {
          rs422_diag_record_timeout_transition(
            current_tick,
            has_valid_frame,
            last_valid_frame_tick);
          g_rs422_comm_timeout_count++;
          g_rs422_comm_state = COMM_TIMEOUT;
        }
      }
      else if (g_rs422_comm_state != COMM_OK)
      {
        if (g_rs422_comm_state == COMM_TIMEOUT)
        {
          const uint32_t recovery_first_valid_tick =
            g_rs422_diag_recovery_first_valid_tick;
          g_rs422_diag_recovery_comm_ok_tick = current_tick;
          g_rs422_diag_recovery_comm_ok_ms =
            rs422_kernel_ticks_to_ms(current_tick);
          g_rs422_diag_recovery_ms = DIAG_TIMESTAMP_NOT_CAPTURED_MS;

          if (recovery_first_valid_tick != UINT32_MAX)
          {
            const uint32_t recovery_ticks =
              current_tick - recovery_first_valid_tick;
            g_rs422_diag_recovery_ms =
              rs422_kernel_ticks_to_ms(recovery_ticks);
          }

          __DMB();
          g_rs422_comm_recovery_count++;
        }

        g_rs422_comm_state = COMM_OK;
      }
    }
    else if ((uint32_t)(current_tick - health_start_tick) >=
             comm_timeout_ticks)
    {
      if (g_rs422_comm_state != COMM_TIMEOUT)
      {
        rs422_diag_record_timeout_transition(
          current_tick,
          has_valid_frame,
          last_valid_frame_tick);
        g_rs422_comm_timeout_count++;
        g_rs422_comm_state = COMM_TIMEOUT;
      }
    }

    g_gateway_free_heap_bytes = (uint32_t)xPortGetFreeHeapSize();
    g_gateway_min_ever_free_heap_bytes =
      (uint32_t)xPortGetMinimumEverFreeHeapSize();
  }
  /* USER CODE END StartHealthTask */
}

void HAL_TIM_PeriodElapsedCallback(TIM_HandleTypeDef *htim)
{
  if (htim->Instance == TIM6)
  {
    HAL_IncTick();
  }
}

void Error_Handler(void)
{
  __disable_irq();
  while (1)
  {
  }
}
